AUTOSAR XML (schema 00044)
package /ECUSystem
  ecu instance ECM: associated-com-i-pdu-group=PduGroup_2aab989138b64636877a7f761b5a08a8_Rx
    can communication controller ECM
    can communication connector CAN_ECM_Connector: comm-controller=ECM
package /Communication/ISignal
  86 x i signal, all with data-type-policy=OVERRIDE:
    ECU_Data_Dwp: init-value=Signal_ECU_Data_Dwp:0.0, length=1, base-type=APPLICATION1, compu-method=DataTypeSemantics/ECU_Data_Dwp_COMPU, system-signal=Signal/ECU_Data_Dwp
    ECU_Data_NXCellDiagRqst: init-value=Signal_ECU_Data_NXCellDiagRqst:0.0, length=2, base-type=APPLICATION2, compu-method=DataTypeSemantics/ECU_Data_NXCellDiagRqst_COMPU, system-signal=Signal/ECU_Data_NXCellDiagRqst
    ECU_Data_Random_Number_Byte{0..7}: init-value=Signal_ECU_Data_Random_Number_Byte{0..7}:0, length=8, base-type=APPLICATION8, compu {phys=raw for raw 0..255}, system-signal=Signal/ECU_Data_Random_Number_Byte{0..7}
    ECU_Data_SymKey1_Byte{0..7}: init-value=Signal_ECU_Data_SymKey1_Byte{0..7}:0, length=8, base-type=APPLICATION8, compu {phys=raw for raw 0..255}, system-signal=Signal/ECU_Data_SymKey1_Byte{0..7}
    ECU_Data_SymKey2_Byte{10..15}: init-value=Signal_ECU_Data_SymKey2_Byte{10..15}:0, length=8, base-type=APPLICATION8, compu {phys=raw for raw 0..255}, system-signal=Signal/ECU_Data_SymKey2_Byte{10..15}
    ECU_Data_SymKey2_Byte8: init-value=Signal_ECU_Data_SymKey2_Byte8:0, length=8, base-type=APPLICATION8, compu {phys=raw for raw 0..255}, system-signal=Signal/ECU_Data_SymKey2_Byte8
    ECU_Data_SymKey2_Byte9: init-value=Signal_ECU_Data_SymKey2_Byte9:0, length=8, base-type=APPLICATION8, compu {phys=raw for raw 0..255}, system-signal=Signal/ECU_Data_SymKey2_Byte9
    NXSI_CALID1_Byte{0..7}: init-value=Signal_NXSI_CALID1_Byte{0..7}:0.0, length=8, base-type=APPLICATION8, compu {phys=raw for raw 0..255}, system-signal=Signal/NXSI_CALID1_Byte{0..7}
    NXSI_CALID2_Byte{10..15}: init-value=Signal_NXSI_CALID2_Byte{10..15}:0.0, length=8, base-type=APPLICATION8, compu {phys=raw for raw 0..255}, system-signal=Signal/NXSI_CALID2_Byte{10..15}
    NXSI_CALID2_Byte8: init-value=Signal_NXSI_CALID2_Byte8:0.0, length=8, base-type=APPLICATION8, compu {phys=raw for raw 0..255}, system-signal=Signal/NXSI_CALID2_Byte8
    NXSI_CALID2_Byte9: init-value=Signal_NXSI_CALID2_Byte9:0.0, length=8, base-type=APPLICATION8, compu {phys=raw for raw 0..255}, system-signal=Signal/NXSI_CALID2_Byte9
    NXSI_CVNSCU_CVN: init-value=Signal_NXSI_CVNSCU_CVN:0.0, length=32, base-type=APPLICATION32, compu {phys=raw for raw 0..2147483647}, system-signal=Signal/NXSI_CVNSCU_CVN
    NXSI_CVNSCU_CVNSt: init-value=Signal_NXSI_CVNSCU_CVNSt:0.0, length=1, base-type=APPLICATION1, compu-method=DataTypeSemantics/NXSI_CVNSCU_CVNSt_COMPU, system-signal=Signal/NXSI_CVNSCU_CVNSt
    NXSI_CVNSCU_HWver: init-value=Signal_NXSI_CVNSCU_HWver:0.0, length=12, base-type=APPLICATION12, compu {phys=raw for raw 0..4095}, system-signal=Signal/NXSI_CVNSCU_HWver
    NXSI_CVNSCU_SWver: init-value=Signal_NXSI_CVNSCU_SWver:0.0, length=12, base-type=APPLICATION12, compu {phys=raw for raw 0..4095}, system-signal=Signal/NXSI_CVNSCU_SWver
    NXSI_Data_DwpRx: init-value=Signal_NXSI_Data_DwpRx:0.0, length=1, base-type=APPLICATION1, compu-method=DataTypeSemantics/NXSI_Data_DwpRx_COMPU, system-signal=Signal/NXSI_Data_DwpRx
    NXSI_Data_NOx: init-value=Signal_NXSI_Data_NOx:0, length=16, base-type=APPLICATION16, compu {phys=raw*0.05-200 for raw 0..65535; unit Unit_ppm}, system-signal=Signal/NXSI_Data_NOx
    NXSI_Data_NOxSt: init-value=Signal_NXSI_Data_NOxSt:0.0, length=2, base-type=APPLICATION2, compu-method=DataTypeSemantics/NXSI_Data_NOxSt_COMPU, system-signal=Signal/NXSI_Data_NOxSt
    NXSI_Data_O2St: init-value=Signal_NXSI_Data_O2St:0.0, length=2, base-type=APPLICATION2, compu-method=DataTypeSemantics/NXSI_Data_O2St_COMPU, system-signal=Signal/NXSI_Data_O2St
    NXSI_Data_O2binary: init-value=Signal_NXSI_Data_O2binary:-0.081596375, length=12, base-type=APPLICATION12, compu {phys=raw*0.3152-100 for raw 0..4095; unit Unit_mV}, system-signal=Signal/NXSI_Data_O2binary
    NXSI_Data_O2linear: init-value=Signal_NXSI_Data_O2linear:-9.39, length=16, base-type=APPLICATION16, compu {phys=raw*0.00061-10 for raw 0..65535; unit Unit_%}, system-signal=Signal/NXSI_Data_O2linear
    NXSI_Data_ProbeTempSt: init-value=Signal_NXSI_Data_ProbeTempSt:0.0, length=2, base-type=APPLICATION2, compu-method=DataTypeSemantics/NXSI_Data_ProbeTempSt_COMPU, system-signal=Signal/NXSI_Data_ProbeTempSt
    NXSI_Data_SCUTempSt: init-value=Signal_NXSI_Data_SCUTempSt:0, length=2, base-type=APPLICATION2, compu-method=DataTypeSemantics/NXSI_Data_SCUTempSt_COMPU, system-signal=Signal/NXSI_Data_SCUTempSt
    NXSI_Data_SecOc_TxToggle: init-value=Signal_NXSI_Data_SecOc_TxToggle:0, length=1, base-type=APPLICATION1, compu-method=DataTypeSemantics/NXSI_Data_SecOc_TxToggle_COMPU, system-signal=Signal/NXSI_Data_SecOc_TxToggle
    NXSI_Data_diagHtr: init-value=Signal_NXSI_Data_diagHtr:0, length=3, base-type=APPLICATION3, compu-method=DataTypeSemantics/NXSI_Data_diagHtr_COMPU, system-signal=Signal/NXSI_Data_diagHtr
    NXSI_Data_diagProbe: init-value=Signal_NXSI_Data_diagProbe:0.0, length=3, base-type=APPLICATION3, compu-method=DataTypeSemantics/NXSI_Data_diagProbe_COMPU, system-signal=Signal/NXSI_Data_diagProbe
    NXSI_Data_diagVltg: init-value=Signal_NXSI_Data_diagVltg:0, length=2, base-type=APPLICATION2, compu-method=DataTypeSemantics/NXSI_Data_diagVltg_COMPU, system-signal=Signal/NXSI_Data_diagVltg
    NXSI_DiagCorrLC_LftCnt: init-value=Signal_NXSI_DiagCorrLC_LftCnt:0.0, length=24, base-type=APPLICATION24, compu {phys=raw for raw 0..16777215; unit Unit_min}, system-signal=Signal/NXSI_DiagCorrLC_LftCnt
    NXSI_DiagCorrLC_NOxPCorr: init-value=Signal_NXSI_DiagCorrLC_NOxPCorr:0.0, length=8, base-type=APPLICATION8, compu {phys=raw*0.005 for raw 0..255}, system-signal=Signal/NXSI_DiagCorrLC_NOxPCorr
    NXSI_DiagCorrLC_O2PCorr: init-value=Signal_NXSI_DiagCorrLC_O2PCorr:0.0, length=8, base-type=APPLICATION8, compu {phys=raw*0.005 for raw 0..255}, system-signal=Signal/NXSI_DiagCorrLC_O2PCorr
    NXSI_DiagCorrLC_diagCOM: init-value=Signal_NXSI_DiagCorrLC_diagCOM:0.0, length=3, base-type=APPLICATION3, compu-method=DataTypeSemantics/NXSI_DiagCorrLC_diagCOM_COMPU, system-signal=Signal/NXSI_DiagCorrLC_diagCOM
    NXSI_DiagCorrLC_diagP1: init-value=Signal_NXSI_DiagCorrLC_diagP1:0.0, length=3, base-type=APPLICATION3, compu-method=DataTypeSemantics/NXSI_DiagCorrLC_diagP1_COMPU, system-signal=Signal/NXSI_DiagCorrLC_diagP1
    NXSI_DiagCorrLC_diagP2: init-value=Signal_NXSI_DiagCorrLC_diagP2:0.0, length=3, base-type=APPLICATION3, compu-method=DataTypeSemantics/NXSI_DiagCorrLC_diagP2_COMPU, system-signal=Signal/NXSI_DiagCorrLC_diagP2
    NXSI_DiagCorrLC_diagVs: init-value=Signal_NXSI_DiagCorrLC_diagVs:0.0, length=3, base-type=APPLICATION3, compu-method=DataTypeSemantics/NXSI_DiagCorrLC_diagVs_COMPU, system-signal=Signal/NXSI_DiagCorrLC_diagVs
    NXSI_KeyResponse_Byte0: init-value=Signal_NXSI_KeyResponse_Byte0:0, length=8, base-type=APPLICATION8, compu-method=DataTypeSemantics/NXSI_KeyResponse_Byte0_COMPU, system-signal=Signal/NXSI_KeyResponse_Byte0
    NXSI_KeyResponse_Byte{1..7}: init-value=Signal_NXSI_KeyResponse_Byte{1..7}:0, length=8, base-type=APPLICATION8, compu {phys=raw for raw 0..255}, system-signal=Signal/NXSI_KeyResponse_Byte{1..7}
    NXSI_MAC_Byte{0..7}: init-value=Signal_NXSI_MAC_Byte{0..7}:0, length=8, base-type=APPLICATION8, compu {phys=raw for raw 0..255}, system-signal=Signal/NXSI_MAC_Byte{0..7}
    NXSI_NH3SD_NXCellDiagSt: init-value=Signal_NXSI_NH3SD_NXCellDiagSt:0.0, length=8, base-type=APPLICATION8, compu-method=DataTypeSemantics/NXSI_NH3SD_NXCellDiagSt_COMPU, system-signal=Signal/NXSI_NH3SD_NXCellDiagSt
    NXSI_NH3SD_NxCellDiagRes: init-value=Signal_NXSI_NH3SD_NxCellDiagRes:0.0, length=8, base-type=APPLICATION8, compu {phys=raw for raw 0..255; unit Unit_%}, system-signal=Signal/NXSI_NH3SD_NxCellDiagRes
    NXSI_NH3SD_RpVs: init-value=Signal_NXSI_NH3SD_RpVs:0.0, length=16, base-type=APPLICATION16, compu {phys=raw*0.01 for raw 0..65535; unit Unit_Ohm}, system-signal=Signal/NXSI_NH3SD_RpVs
    NXSI_NH3SD_SupplyVltg: init-value=Signal_NXSI_NH3SD_SupplyVltg:0.0, length=16, base-type=APPLICATION16, compu {phys=raw*0.5 for raw 0..65535; unit Unit_mV}, system-signal=Signal/NXSI_NH3SD_SupplyVltg
    NXSI_NH3SD_corNH3: init-value=Signal_NXSI_NH3SD_corNH3:0.0, length=16, base-type=APPLICATION16, compu {phys=raw*0.005 for raw 0..65535}, system-signal=Signal/NXSI_NH3SD_corNH3
package /Signal
  86 x system signal:
    ECU_Data_Dwp: compu-method=DataTypeSemantics/ECU_Data_Dwp_COMPU
    ECU_Data_NXCellDiagRqst: compu-method=DataTypeSemantics/ECU_Data_NXCellDiagRqst_COMPU
    ECU_Data_Random_Number_Byte{0..7}: compu {phys=raw for raw 0..255}
    ECU_Data_SymKey1_Byte{0..7}: compu {phys=raw for raw 0..255}
    ECU_Data_SymKey2_Byte{10..15}: compu {phys=raw for raw 0..255}
    ECU_Data_SymKey2_Byte8: compu {phys=raw for raw 0..255}
    ECU_Data_SymKey2_Byte9: compu {phys=raw for raw 0..255}
    NXSI_CALID1_Byte{0..7}: compu {phys=raw for raw 0..255}
    NXSI_CALID2_Byte{10..15}: compu {phys=raw for raw 0..255}
    NXSI_CALID2_Byte8: compu {phys=raw for raw 0..255}
    NXSI_CALID2_Byte9: compu {phys=raw for raw 0..255}
    NXSI_CVNSCU_CVN: compu {phys=raw for raw 0..2147483647}
    NXSI_CVNSCU_CVNSt: compu-method=DataTypeSemantics/NXSI_CVNSCU_CVNSt_COMPU
    NXSI_CVNSCU_HWver: compu {phys=raw for raw 0..4095}
    NXSI_CVNSCU_SWver: compu {phys=raw for raw 0..4095}
    NXSI_Data_DwpRx: compu-method=DataTypeSemantics/NXSI_Data_DwpRx_COMPU
    NXSI_Data_NOx: compu {phys=raw*0.05-200 for raw 0..65535; unit Unit_ppm}
    NXSI_Data_NOxSt: compu-method=DataTypeSemantics/NXSI_Data_NOxSt_COMPU
    NXSI_Data_O2St: compu-method=DataTypeSemantics/NXSI_Data_O2St_COMPU
    NXSI_Data_O2binary: compu {phys=raw*0.3152-100 for raw 0..4095; unit Unit_mV}
    NXSI_Data_O2linear: compu {phys=raw*0.00061-10 for raw 0..65535; unit Unit_%}
    NXSI_Data_ProbeTempSt: compu-method=DataTypeSemantics/NXSI_Data_ProbeTempSt_COMPU
    NXSI_Data_SCUTempSt: compu-method=DataTypeSemantics/NXSI_Data_SCUTempSt_COMPU
    NXSI_Data_SecOc_TxToggle: compu-method=DataTypeSemantics/NXSI_Data_SecOc_TxToggle_COMPU
    NXSI_Data_diagHtr: compu-method=DataTypeSemantics/NXSI_Data_diagHtr_COMPU
    NXSI_Data_diagProbe: compu-method=DataTypeSemantics/NXSI_Data_diagProbe_COMPU
    NXSI_Data_diagVltg: compu-method=DataTypeSemantics/NXSI_Data_diagVltg_COMPU
    NXSI_DiagCorrLC_LftCnt: compu {phys=raw for raw 0..16777215; unit Unit_min}
    NXSI_DiagCorrLC_NOxPCorr: compu {phys=raw*0.005 for raw 0..255}
    NXSI_DiagCorrLC_O2PCorr: compu {phys=raw*0.005 for raw 0..255}
    NXSI_DiagCorrLC_diagCOM: compu-method=DataTypeSemantics/NXSI_DiagCorrLC_diagCOM_COMPU
    NXSI_DiagCorrLC_diagP1: compu-method=DataTypeSemantics/NXSI_DiagCorrLC_diagP1_COMPU
    NXSI_DiagCorrLC_diagP2: compu-method=DataTypeSemantics/NXSI_DiagCorrLC_diagP2_COMPU
    NXSI_DiagCorrLC_diagVs: compu-method=DataTypeSemantics/NXSI_DiagCorrLC_diagVs_COMPU
    NXSI_KeyResponse_Byte0: compu-method=DataTypeSemantics/NXSI_KeyResponse_Byte0_COMPU
    NXSI_KeyResponse_Byte{1..7}: compu {phys=raw for raw 0..255}
    NXSI_MAC_Byte{0..7}: compu {phys=raw for raw 0..255}
    NXSI_NH3SD_NXCellDiagSt: compu-method=DataTypeSemantics/NXSI_NH3SD_NXCellDiagSt_COMPU
    NXSI_NH3SD_NxCellDiagRes: compu {phys=raw for raw 0..255; unit Unit_%}
    NXSI_NH3SD_RpVs: compu {phys=raw*0.01 for raw 0..65535; unit Unit_Ohm}
    NXSI_NH3SD_SupplyVltg: compu {phys=raw*0.5 for raw 0..65535; unit Unit_mV}
    NXSI_NH3SD_corNH3: compu {phys=raw*0.005 for raw 0..65535}
package /DataType/DataTypeSemantics
  compu method ECU_Data_Dwp_COMPU: phys=raw for raw 0..1, 1=Dew_point_end_reached (New_Short_Label), 0=Dew_point_end_not_reached (New_Short_Label); unit Unit_SED
  compu method ECU_Data_Dwp_COMPU: phys=raw for raw 0..1, 1=Dew_point_end_reached (New_Short_Label), 0=Dew_point_end_not_reached (New_Short_Label); unit Unit_SED
  compu method ECU_Data_NXCellDiagRqst_COMPU: phys=raw for raw 0..3, 3=not_applicable (New_Short_Label), 2=active_in_idle/thrust (New_Short_Label), 1=active_in_after_run (New_Short_Label), 0=not_active (New_Short_Label); unit Unit_SED
  compu method ECU_Data_NXCellDiagRqst_COMPU: phys=raw for raw 0..3, 3=not_applicable (New_Short_Label), 2=active_in_idle/thrust (New_Short_Label), 1=active_in_after_run (New_Short_Label), 0=not_active (New_Short_Label); unit Unit_SED
  compu method ECU_Data_Random_Number_Byte{0..7}_COMPU: phys=raw for raw 0..255
  compu method ECU_Data_SymKey1_Byte{0..7}_COMPU: phys=raw for raw 0..255
  compu method ECU_Data_SymKey2_Byte{10..15}_COMPU: phys=raw for raw 0..255
  compu method ECU_Data_SymKey2_Byte8_COMPU: phys=raw for raw 0..255
  compu method ECU_Data_SymKey2_Byte9_COMPU: phys=raw for raw 0..255
  compu method NXSI_CALID1_Byte{0..7}_COMPU: phys=raw for raw 0..255
  compu method NXSI_CALID2_Byte{10..15}_COMPU: phys=raw for raw 0..255
  compu method NXSI_CALID2_Byte8_COMPU: phys=raw for raw 0..255
  compu method NXSI_CALID2_Byte9_COMPU: phys=raw for raw 0..255
  compu method NXSI_CVNSCU_CVNSt_COMPU: phys=raw for raw 0..1, 1=calculation_done (New_Short_Label), 0=calculation_in_progress (New_Short_Label)
  compu method NXSI_CVNSCU_CVNSt_COMPU: phys=raw for raw 0..1, 1=calculation_done (New_Short_Label), 0=calculation_in_progress (New_Short_Label)
  compu method NXSI_CVNSCU_CVN_COMPU: phys=raw for raw 0..2147483647
  compu method NXSI_CVNSCU_HWver_COMPU: phys=raw for raw 0..4095
  compu method NXSI_CVNSCU_SWver_COMPU: phys=raw for raw 0..4095
  compu method NXSI_Data_DwpRx_COMPU: phys=raw for raw 0..1, 1=reached (New_Short_Label), 0=not_reached (New_Short_Label); unit Unit_SED
  compu method NXSI_Data_DwpRx_COMPU: phys=raw for raw 0..1, 1=reached (New_Short_Label), 0=not_reached (New_Short_Label); unit Unit_SED
  compu method NXSI_Data_NOxSt_COMPU: phys=raw for raw 0..3, 3=reserved (New_Short_Label), 2=YELLOW(out_of_specification) (New_Short_Label), 1=GREEN(valid,_in_specification) (New_Short_Label), 0=RED(invalid) (New_Short_Label); unit Unit_0
  compu method NXSI_Data_NOxSt_COMPU: phys=raw for raw 0..3, 3=reserved (New_Short_Label), 2=YELLOW(out_of_specification) (New_Short_Label), 1=GREEN(valid,_in_specification) (New_Short_Label), 0=RED(invalid) (New_Short_Label); unit Unit_0
  compu method NXSI_Data_NOx_COMPU: phys=raw*0.05-200 for raw 0..65535; unit Unit_ppm
  compu method NXSI_Data_O2St_COMPU: phys=raw for raw 0..3, 3=reserved (New_Short_Label), 2=YELLOW(out_of_specification) (New_Short_Label), 1=GREEN(valid,_in_specification) (New_Short_Label), 0=RED(invalid) (New_Short_Label); unit Unit_0
  compu method NXSI_Data_O2St_COMPU: phys=raw for raw 0..3, 3=reserved (New_Short_Label), 2=YELLOW(out_of_specification) (New_Short_Label), 1=GREEN(valid,_in_specification) (New_Short_Label), 0=RED(invalid) (New_Short_Label); unit Unit_0
  compu method NXSI_Data_O2binary_COMPU: phys=raw*0.3152-100 for raw 0..4095; unit Unit_mV
  compu method NXSI_Data_O2linear_COMPU: phys=raw*0.00061-10 for raw 0..65535; unit Unit_%
  compu method NXSI_Data_ProbeTempSt_COMPU: phys=raw for raw 0..3, 3=reserved (New_Short_Label), 2=reserved (New_Short_Label), 1=reached_CL_operation_point (New_Short_Label), 0=not_reached_CL_operation_point (New_Short_Label)
  compu method NXSI_Data_ProbeTempSt_COMPU: phys=raw for raw 0..3, 3=reserved (New_Short_Label), 2=reserved (New_Short_Label), 1=reached_CL_operation_point (New_Short_Label), 0=not_reached_CL_operation_point (New_Short_Label)
  compu method NXSI_Data_SCUTempSt_COMPU: phys=raw for raw 0..3, 3=reserved (New_Short_Label), 2=SCU_over_temperature (New_Short_Label), 1=SCU_temperature_in_range (New_Short_Label), 0=SCU_temperature_not_available (New_Short_Label)
  compu method NXSI_Data_SCUTempSt_COMPU: phys=raw for raw 0..3, 3=reserved (New_Short_Label), 2=SCU_over_temperature (New_Short_Label), 1=SCU_temperature_in_range (New_Short_Label), 0=SCU_temperature_not_available (New_Short_Label)
  compu method NXSI_Data_SecOc_TxToggle_COMPU: phys=raw for raw 0..1, 1=Toggle_set (New_Short_Label), 0=Toggle_reset (New_Short_Label)
  compu method NXSI_Data_SecOc_TxToggle_COMPU: phys=raw for raw 0..1, 1=Toggle_set (New_Short_Label), 0=Toggle_reset (New_Short_Label)
  compu method NXSI_Data_diagHtr_COMPU: phys=raw for raw 0..7, 7=reserved (New_Short_Label), 6=reserved (New_Short_Label), 5=reserved (New_Short_Label), 4=open_circuit (New_Short_Label), 3=short_to_battery (New_Short_Label), 2=short_to_GND (New_Short_Label), 1=no_error (New_Short_Label), 0=diag_not_executed (New_Short_Label); unit Unit_0
  compu method NXSI_Data_diagHtr_COMPU: phys=raw for raw 0..7, 7=reserved (New_Short_Label), 6=reserved (New_Short_Label), 5=reserved (New_Short_Label), 4=open_circuit (New_Short_Label), 3=short_to_battery (New_Short_Label), 2=short_to_GND (New_Short_Label), 1=no_error (New_Short_Label), 0=diag_not_executed (New_Short_Label); unit Unit_0
  compu method NXSI_Data_diagProbe_COMPU: phys=raw for raw 0..7, 7=reserved (New_Short_Label), 6=reserved (New_Short_Label), 5=reserved (New_Short_Label), 4=open_circuit (New_Short_Label), 3=short_to_battery (New_Short_Label), 2=short_to_GND (New_Short_Label), 1=no_error (New_Short_Label), 0=diag_not_executed (New_Short_Label); unit Unit_0
  compu method NXSI_Data_diagProbe_COMPU: phys=raw for raw 0..7, 7=reserved (New_Short_Label), 6=reserved (New_Short_Label), 5=reserved (New_Short_Label), 4=open_circuit (New_Short_Label), 3=short_to_battery (New_Short_Label), 2=short_to_GND (New_Short_Label), 1=no_error (New_Short_Label), 0=diag_not_executed (New_Short_Label); unit Unit_0
  compu method NXSI_Data_diagVltg_COMPU: phys=raw for raw 0..3, 3=Battery_undervoltage (New_Short_Label), 2=Battery_OV(includes_fast_OV) (New_Short_Label), 1=no_error (New_Short_Label), 0=diagnosis_not_executed (New_Short_Label)
  compu method NXSI_Data_diagVltg_COMPU: phys=raw for raw 0..3, 3=Battery_undervoltage (New_Short_Label), 2=Battery_OV(includes_fast_OV) (New_Short_Label), 1=no_error (New_Short_Label), 0=diagnosis_not_executed (New_Short_Label)
  compu method NXSI_DiagCorrLC_LftCnt_COMPU: phys=raw for raw 0..16777215; unit Unit_min
  compu method NXSI_DiagCorrLC_NOxPCorr_COMPU: phys=raw*0.005 for raw 0..255
  compu method NXSI_DiagCorrLC_O2PCorr_COMPU: phys=raw*0.005 for raw 0..255
  compu method NXSI_DiagCorrLC_diagCOM_COMPU: phys=raw for raw 0..7, 7=reserved (New_Short_Label), 6=reserved (New_Short_Label), 5=reserved (New_Short_Label), 4=open_circuit (New_Short_Label), 3=short_to_battery (New_Short_Label), 2=short_to_GND (New_Short_Label), 1=no_error (New_Short_Label), 0=diag_not_executed (New_Short_Label); unit Unit_0
  compu method NXSI_DiagCorrLC_diagCOM_COMPU: phys=raw for raw 0..7, 7=reserved (New_Short_Label), 6=reserved (New_Short_Label), 5=reserved (New_Short_Label), 4=open_circuit (New_Short_Label), 3=short_to_battery (New_Short_Label), 2=short_to_GND (New_Short_Label), 1=no_error (New_Short_Label), 0=diag_not_executed (New_Short_Label); unit Unit_0
  compu method NXSI_DiagCorrLC_diagP1_COMPU: phys=raw for raw 0..7, 7=reserved (New_Short_Label), 6=reserved (New_Short_Label), 5=reserved (New_Short_Label), 4=open_circuit (New_Short_Label), 3=short_to_battery (New_Short_Label), 2=short_to_GND (New_Short_Label), 1=no_error (New_Short_Label), 0=diag_not_executed (New_Short_Label); unit Unit_0
  compu method NXSI_DiagCorrLC_diagP1_COMPU: phys=raw for raw 0..7, 7=reserved (New_Short_Label), 6=reserved (New_Short_Label), 5=reserved (New_Short_Label), 4=open_circuit (New_Short_Label), 3=short_to_battery (New_Short_Label), 2=short_to_GND (New_Short_Label), 1=no_error (New_Short_Label), 0=diag_not_executed (New_Short_Label); unit Unit_0
  compu method NXSI_DiagCorrLC_diagP2_COMPU: phys=raw for raw 0..7, 7=reserved (New_Short_Label), 6=reserved (New_Short_Label), 5=reserved (New_Short_Label), 4=open_circuit (New_Short_Label), 3=short_to_battery (New_Short_Label), 2=short_to_GND (New_Short_Label), 1=no_error (New_Short_Label), 0=diag_not_executed (New_Short_Label); unit Unit_0
  compu method NXSI_DiagCorrLC_diagP2_COMPU: phys=raw for raw 0..7, 7=reserved (New_Short_Label), 6=reserved (New_Short_Label), 5=reserved (New_Short_Label), 4=open_circuit (New_Short_Label), 3=short_to_battery (New_Short_Label), 2=short_to_GND (New_Short_Label), 1=no_error (New_Short_Label), 0=diag_not_executed (New_Short_Label); unit Unit_0
  compu method NXSI_DiagCorrLC_diagVs_COMPU: phys=raw for raw 0..7, 7=reserved (New_Short_Label), 6=reserved (New_Short_Label), 5=reserved (New_Short_Label), 4=open_circuit (New_Short_Label), 3=short_to_battery (New_Short_Label), 2=short_to_GND (New_Short_Label), 1=no_error (New_Short_Label), 0=diag_not_executed (New_Short_Label); unit Unit_0
  compu method NXSI_DiagCorrLC_diagVs_COMPU: phys=raw for raw 0..7, 7=reserved (New_Short_Label), 6=reserved (New_Short_Label), 5=reserved (New_Short_Label), 4=open_circuit (New_Short_Label), 3=short_to_battery (New_Short_Label), 2=short_to_GND (New_Short_Label), 1=no_error (New_Short_Label), 0=diag_not_executed (New_Short_Label); unit Unit_0
  compu method NXSI_KeyResponse_Byte0_COMPU: phys=raw for raw 0..255, 1=Negative_response (New_Short_Label), 0=Positive_response (New_Short_Label)
  compu method NXSI_KeyResponse_Byte0_COMPU: phys=raw for raw 0..255, 1=Negative_response (New_Short_Label), 0=Positive_response (New_Short_Label)
  compu method NXSI_KeyResponse_Byte{1..7}_COMPU: phys=raw for raw 0..255
  compu method NXSI_MAC_Byte{0..7}_COMPU: phys=raw for raw 0..255
  compu method NXSI_NH3SD_NXCellDiagSt_COMPU: phys=raw for raw 0..255, 3=reserved (New_Short_Label), 4=completed (New_Short_Label), 2=aborted (New_Short_Label), 1=active (New_Short_Label), 0=inactive (New_Short_Label)
  compu method NXSI_NH3SD_NXCellDiagSt_COMPU: phys=raw for raw 0..255, 3=reserved (New_Short_Label), 4=completed (New_Short_Label), 2=aborted (New_Short_Label), 1=active (New_Short_Label), 0=inactive (New_Short_Label)
  compu method NXSI_NH3SD_NxCellDiagRes_COMPU: phys=raw for raw 0..255; unit Unit_%
  compu method NXSI_NH3SD_RpVs_COMPU: phys=raw*0.01 for raw 0..65535; unit Unit_Ohm
  compu method NXSI_NH3SD_SupplyVltg_COMPU: phys=raw*0.5 for raw 0..65535; unit Unit_mV
  compu method NXSI_NH3SD_corNH3_COMPU: phys=raw*0.005 for raw 0..65535
package /DataType/DataTypeSemantics/SwBaseTypes
  8 x base type, all with category=FIXED_LENGTH, base-type-encoding=NONE:
    APPLICATION1: base-type-size=1
    APPLICATION12: base-type-size=12
    APPLICATION16: base-type-size=16
    APPLICATION2: base-type-size=2
    APPLICATION24: base-type-size=24
    APPLICATION3: base-type-size=3
    APPLICATION32: base-type-size=32
    APPLICATION8: base-type-size=8
package /DataType/Unit
  7 x unit, all with factor-si-to-unit=1:
    %: display-name=Unit_%
    0: display-name=Unit_0
    Ohm: display-name=Unit_Ohm
    SED: display-name=Unit_SED
    mV: display-name=Unit_mV
    min: display-name=Unit_min
    ppm: display-name=Unit_ppm
package /VehicleTopology
  can cluster CAN_ECM_Cluster: protocol-name=CAN-FD
    can physical channel PhCn_CAN_ECM: comm-connectors=CAN_ECM_Connector
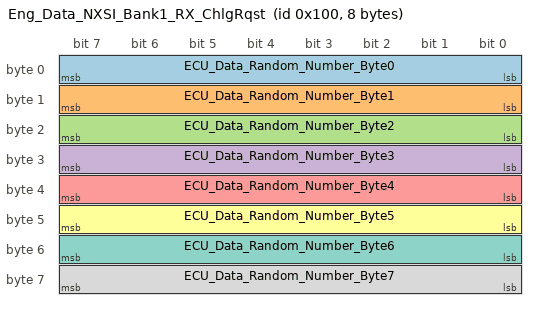
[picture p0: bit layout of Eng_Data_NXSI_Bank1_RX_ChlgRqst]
      frame Eng_Data_NXSI_Bank1_RX_ChlgRqst: id 0x100, from ECM, frame-length=8, can-addressing-mode=STANDARD, can-fd-frame-support=false, can-frame-rx-behavior=CAN-20, can-frame-tx-behavior=CAN-20
        carries pdu Eng_Data_NXSI_Bank1_RX_ChlgRqst: packing-byte-order=big-endian, start-position=7
        pdu Eng_Data_NXSI_Bank1_RX_ChlgRqst: length=8, unused-bit-pattern=0
          signal ECU_Data_Random_Number_Byte0: start 7, 8 bit, big-endian, data-type-policy=OVERRIDE, init-value=Signal_ECU_Data_Random_Number_Byte0:0, base-type=APPLICATION8, compu {phys=raw for raw 0..255}, transfer-property=PENDING
          signal ECU_Data_Random_Number_Byte1: start 15, 8 bit, big-endian, data-type-policy=OVERRIDE, init-value=Signal_ECU_Data_Random_Number_Byte1:0, base-type=APPLICATION8, compu {phys=raw for raw 0..255}, transfer-property=PENDING
          signal ECU_Data_Random_Number_Byte2: start 23, 8 bit, big-endian, data-type-policy=OVERRIDE, init-value=Signal_ECU_Data_Random_Number_Byte2:0, base-type=APPLICATION8, compu {phys=raw for raw 0..255}, transfer-property=PENDING
          signal ECU_Data_Random_Number_Byte3: start 31, 8 bit, big-endian, data-type-policy=OVERRIDE, init-value=Signal_ECU_Data_Random_Number_Byte3:0, base-type=APPLICATION8, compu {phys=raw for raw 0..255}, transfer-property=PENDING
          signal ECU_Data_Random_Number_Byte4: start 39, 8 bit, big-endian, data-type-policy=OVERRIDE, init-value=Signal_ECU_Data_Random_Number_Byte4:0, base-type=APPLICATION8, compu {phys=raw for raw 0..255}, transfer-property=PENDING
          signal ECU_Data_Random_Number_Byte5: start 47, 8 bit, big-endian, data-type-policy=OVERRIDE, init-value=Signal_ECU_Data_Random_Number_Byte5:0, base-type=APPLICATION8, compu {phys=raw for raw 0..255}, transfer-property=PENDING
          signal ECU_Data_Random_Number_Byte6: start 55, 8 bit, big-endian, data-type-policy=OVERRIDE, init-value=Signal_ECU_Data_Random_Number_Byte6:0, base-type=APPLICATION8, compu {phys=raw for raw 0..255}, transfer-property=PENDING
          signal ECU_Data_Random_Number_Byte7: start 63, 8 bit, big-endian, data-type-policy=OVERRIDE, init-value=Signal_ECU_Data_Random_Number_Byte7:0, base-type=APPLICATION8, compu {phys=raw for raw 0..255}, transfer-property=PENDING
      frame Eng_Data_NXSI_Bank1_RX_Data: id 0x3A5, from ECM, frame-length=8, can-addressing-mode=STANDARD, can-fd-frame-support=false, can-frame-rx-behavior=CAN-20, can-frame-tx-behavior=CAN-20
        carries pdu Eng_Data_NXSI_Bank1_RX_Data: packing-byte-order=big-endian, start-position=7
        pdu Eng_Data_NXSI_Bank1_RX_Data: length=8, transmission-mode-true-timing=cyclic-timing=time-period=0.1, unused-bit-pattern=0
          signal ECU_Data_Dwp: start 0, 1 bit, big-endian, data-type-policy=OVERRIDE, init-value=Signal_ECU_Data_Dwp:0, base-type=APPLICATION1, compu-method=DataTypeSemantics/ECU_Data_Dwp_COMPU, transfer-property=PENDING
          signal ECU_Data_NXCellDiagRqst: start 2, 2 bit, big-endian, data-type-policy=OVERRIDE, init-value=Signal_ECU_Data_NXCellDiagRqst:0, base-type=APPLICATION2, compu-method=DataTypeSemantics/ECU_Data_NXCellDiagRqst_COMPU, transfer-property=PENDING
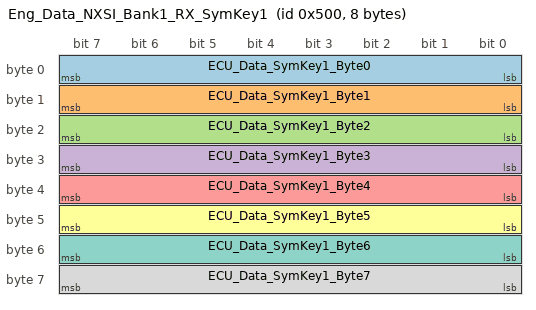
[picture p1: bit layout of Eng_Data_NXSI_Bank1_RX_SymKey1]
      frame Eng_Data_NXSI_Bank1_RX_SymKey1: id 0x500, from ECM, frame-length=8, can-addressing-mode=STANDARD, can-fd-frame-support=false, can-frame-rx-behavior=CAN-20, can-frame-tx-behavior=CAN-20
        carries pdu Eng_Data_NXSI_Bank1_RX_SymKey1: packing-byte-order=big-endian, start-position=7
        pdu Eng_Data_NXSI_Bank1_RX_SymKey1: length=8, unused-bit-pattern=0
          signal ECU_Data_SymKey1_Byte0: start 7, 8 bit, big-endian, data-type-policy=OVERRIDE, init-value=Signal_ECU_Data_SymKey1_Byte0:0, base-type=APPLICATION8, compu {phys=raw for raw 0..255}, transfer-property=PENDING
          signal ECU_Data_SymKey1_Byte1: start 15, 8 bit, big-endian, data-type-policy=OVERRIDE, init-value=Signal_ECU_Data_SymKey1_Byte1:0, base-type=APPLICATION8, compu {phys=raw for raw 0..255}, transfer-property=PENDING
          signal ECU_Data_SymKey1_Byte2: start 23, 8 bit, big-endian, data-type-policy=OVERRIDE, init-value=Signal_ECU_Data_SymKey1_Byte2:0, base-type=APPLICATION8, compu {phys=raw for raw 0..255}, transfer-property=PENDING
          signal ECU_Data_SymKey1_Byte3: start 31, 8 bit, big-endian, data-type-policy=OVERRIDE, init-value=Signal_ECU_Data_SymKey1_Byte3:0, base-type=APPLICATION8, compu {phys=raw for raw 0..255}, transfer-property=PENDING
          signal ECU_Data_SymKey1_Byte4: start 39, 8 bit, big-endian, data-type-policy=OVERRIDE, init-value=Signal_ECU_Data_SymKey1_Byte4:0, base-type=APPLICATION8, compu {phys=raw for raw 0..255}, transfer-property=PENDING
          signal ECU_Data_SymKey1_Byte5: start 47, 8 bit, big-endian, data-type-policy=OVERRIDE, init-value=Signal_ECU_Data_SymKey1_Byte5:0, base-type=APPLICATION8, compu {phys=raw for raw 0..255}, transfer-property=PENDING
          signal ECU_Data_SymKey1_Byte6: start 55, 8 bit, big-endian, data-type-policy=OVERRIDE, init-value=Signal_ECU_Data_SymKey1_Byte6:0, base-type=APPLICATION8, compu {phys=raw for raw 0..255}, transfer-property=PENDING
          signal ECU_Data_SymKey1_Byte7: start 63, 8 bit, big-endian, data-type-policy=OVERRIDE, init-value=Signal_ECU_Data_SymKey1_Byte7:0, base-type=APPLICATION8, compu {phys=raw for raw 0..255}, transfer-property=PENDING
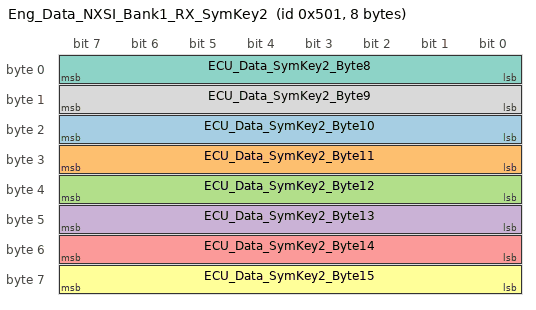
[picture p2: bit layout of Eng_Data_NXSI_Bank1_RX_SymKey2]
      frame Eng_Data_NXSI_Bank1_RX_SymKey2: id 0x501, from ECM, frame-length=8, can-addressing-mode=STANDARD, can-fd-frame-support=false, can-frame-rx-behavior=CAN-20, can-frame-tx-behavior=CAN-20
        carries pdu Eng_Data_NXSI_Bank1_RX_SymKey2: packing-byte-order=big-endian, start-position=7
        pdu Eng_Data_NXSI_Bank1_RX_SymKey2: length=8, unused-bit-pattern=0
          signal ECU_Data_SymKey2_Byte10: start 23, 8 bit, big-endian, data-type-policy=OVERRIDE, init-value=Signal_ECU_Data_SymKey2_Byte10:0, base-type=APPLICATION8, compu {phys=raw for raw 0..255}, transfer-property=PENDING
          signal ECU_Data_SymKey2_Byte11: start 31, 8 bit, big-endian, data-type-policy=OVERRIDE, init-value=Signal_ECU_Data_SymKey2_Byte11:0, base-type=APPLICATION8, compu {phys=raw for raw 0..255}, transfer-property=PENDING
          signal ECU_Data_SymKey2_Byte12: start 39, 8 bit, big-endian, data-type-policy=OVERRIDE, init-value=Signal_ECU_Data_SymKey2_Byte12:0, base-type=APPLICATION8, compu {phys=raw for raw 0..255}, transfer-property=PENDING
          signal ECU_Data_SymKey2_Byte13: start 47, 8 bit, big-endian, data-type-policy=OVERRIDE, init-value=Signal_ECU_Data_SymKey2_Byte13:0, base-type=APPLICATION8, compu {phys=raw for raw 0..255}, transfer-property=PENDING
          signal ECU_Data_SymKey2_Byte14: start 55, 8 bit, big-endian, data-type-policy=OVERRIDE, init-value=Signal_ECU_Data_SymKey2_Byte14:0, base-type=APPLICATION8, compu {phys=raw for raw 0..255}, transfer-property=PENDING
          signal ECU_Data_SymKey2_Byte15: start 63, 8 bit, big-endian, data-type-policy=OVERRIDE, init-value=Signal_ECU_Data_SymKey2_Byte15:0, base-type=APPLICATION8, compu {phys=raw for raw 0..255}, transfer-property=PENDING
          signal ECU_Data_SymKey2_Byte8: start 7, 8 bit, big-endian, data-type-policy=OVERRIDE, init-value=Signal_ECU_Data_SymKey2_Byte8:0, base-type=APPLICATION8, compu {phys=raw for raw 0..255}, transfer-property=PENDING
          signal ECU_Data_SymKey2_Byte9: start 15, 8 bit, big-endian, data-type-policy=OVERRIDE, init-value=Signal_ECU_Data_SymKey2_Byte9:0, base-type=APPLICATION8, compu {phys=raw for raw 0..255}, transfer-property=PENDING
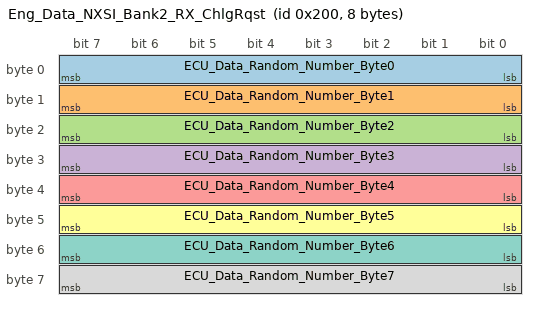
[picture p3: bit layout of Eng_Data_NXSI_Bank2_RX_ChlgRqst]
      frame Eng_Data_NXSI_Bank2_RX_ChlgRqst: id 0x200, from ECM, frame-length=8, can-addressing-mode=STANDARD, can-fd-frame-support=false, can-frame-rx-behavior=CAN-20, can-frame-tx-behavior=CAN-20
        carries pdu Eng_Data_NXSI_Bank2_RX_ChlgRqst: packing-byte-order=big-endian, start-position=7
        pdu Eng_Data_NXSI_Bank2_RX_ChlgRqst: length=8, unused-bit-pattern=0
          signal ECU_Data_Random_Number_Byte0: start 7, 8 bit, big-endian, data-type-policy=OVERRIDE, init-value=Signal_ECU_Data_Random_Number_Byte0:0, base-type=APPLICATION8, compu {phys=raw for raw 0..255}, transfer-property=PENDING
          signal ECU_Data_Random_Number_Byte1: start 15, 8 bit, big-endian, data-type-policy=OVERRIDE, init-value=Signal_ECU_Data_Random_Number_Byte1:0, base-type=APPLICATION8, compu {phys=raw for raw 0..255}, transfer-property=PENDING
          signal ECU_Data_Random_Number_Byte2: start 23, 8 bit, big-endian, data-type-policy=OVERRIDE, init-value=Signal_ECU_Data_Random_Number_Byte2:0, base-type=APPLICATION8, compu {phys=raw for raw 0..255}, transfer-property=PENDING
          signal ECU_Data_Random_Number_Byte3: start 31, 8 bit, big-endian, data-type-policy=OVERRIDE, init-value=Signal_ECU_Data_Random_Number_Byte3:0, base-type=APPLICATION8, compu {phys=raw for raw 0..255}, transfer-property=PENDING
          signal ECU_Data_Random_Number_Byte4: start 39, 8 bit, big-endian, data-type-policy=OVERRIDE, init-value=Signal_ECU_Data_Random_Number_Byte4:0, base-type=APPLICATION8, compu {phys=raw for raw 0..255}, transfer-property=PENDING
          signal ECU_Data_Random_Number_Byte5: start 47, 8 bit, big-endian, data-type-policy=OVERRIDE, init-value=Signal_ECU_Data_Random_Number_Byte5:0, base-type=APPLICATION8, compu {phys=raw for raw 0..255}, transfer-property=PENDING
          signal ECU_Data_Random_Number_Byte6: start 55, 8 bit, big-endian, data-type-policy=OVERRIDE, init-value=Signal_ECU_Data_Random_Number_Byte6:0, base-type=APPLICATION8, compu {phys=raw for raw 0..255}, transfer-property=PENDING
          signal ECU_Data_Random_Number_Byte7: start 63, 8 bit, big-endian, data-type-policy=OVERRIDE, init-value=Signal_ECU_Data_Random_Number_Byte7:0, base-type=APPLICATION8, compu {phys=raw for raw 0..255}, transfer-property=PENDING
      frame Eng_Data_NXSI_Bank2_RX_Data: id 0x2A5, from ECM, frame-length=8, can-addressing-mode=STANDARD, can-fd-frame-support=false, can-frame-rx-behavior=CAN-20, can-frame-tx-behavior=CAN-20
        carries pdu Eng_Data_NXSI_Bank2_RX_Data: packing-byte-order=big-endian, start-position=7
        pdu Eng_Data_NXSI_Bank2_RX_Data: length=8, transmission-mode-true-timing=cyclic-timing=time-period=0.1, unused-bit-pattern=0
          signal ECU_Data_Dwp: start 0, 1 bit, big-endian, data-type-policy=OVERRIDE, init-value=Signal_ECU_Data_Dwp:0, base-type=APPLICATION1, compu-method=DataTypeSemantics/ECU_Data_Dwp_COMPU, transfer-property=PENDING
          signal ECU_Data_NXCellDiagRqst: start 2, 2 bit, big-endian, data-type-policy=OVERRIDE, init-value=Signal_ECU_Data_NXCellDiagRqst:0, base-type=APPLICATION2, compu-method=DataTypeSemantics/ECU_Data_NXCellDiagRqst_COMPU, transfer-property=PENDING
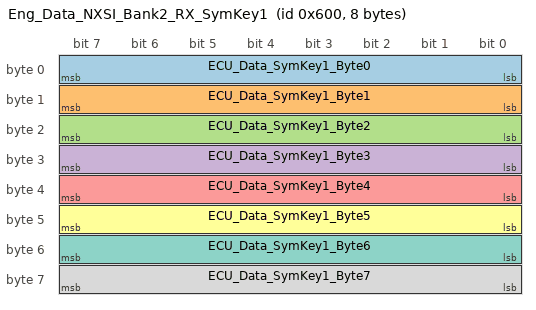
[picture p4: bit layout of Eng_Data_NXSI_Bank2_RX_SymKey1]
      frame Eng_Data_NXSI_Bank2_RX_SymKey1: id 0x600, from ECM, frame-length=8, can-addressing-mode=STANDARD, can-fd-frame-support=false, can-frame-rx-behavior=CAN-20, can-frame-tx-behavior=CAN-20
        carries pdu Eng_Data_NXSI_Bank2_RX_SymKey1: packing-byte-order=big-endian, start-position=7
        pdu Eng_Data_NXSI_Bank2_RX_SymKey1: length=8, unused-bit-pattern=0
          signal ECU_Data_SymKey1_Byte0: start 7, 8 bit, big-endian, data-type-policy=OVERRIDE, init-value=Signal_ECU_Data_SymKey1_Byte0:0, base-type=APPLICATION8, compu {phys=raw for raw 0..255}, transfer-property=PENDING
          signal ECU_Data_SymKey1_Byte1: start 15, 8 bit, big-endian, data-type-policy=OVERRIDE, init-value=Signal_ECU_Data_SymKey1_Byte1:0, base-type=APPLICATION8, compu {phys=raw for raw 0..255}, transfer-property=PENDING
          signal ECU_Data_SymKey1_Byte2: start 23, 8 bit, big-endian, data-type-policy=OVERRIDE, init-value=Signal_ECU_Data_SymKey1_Byte2:0, base-type=APPLICATION8, compu {phys=raw for raw 0..255}, transfer-property=PENDING
          signal ECU_Data_SymKey1_Byte3: start 31, 8 bit, big-endian, data-type-policy=OVERRIDE, init-value=Signal_ECU_Data_SymKey1_Byte3:0, base-type=APPLICATION8, compu {phys=raw for raw 0..255}, transfer-property=PENDING
          signal ECU_Data_SymKey1_Byte4: start 39, 8 bit, big-endian, data-type-policy=OVERRIDE, init-value=Signal_ECU_Data_SymKey1_Byte4:0, base-type=APPLICATION8, compu {phys=raw for raw 0..255}, transfer-property=PENDING
          signal ECU_Data_SymKey1_Byte5: start 47, 8 bit, big-endian, data-type-policy=OVERRIDE, init-value=Signal_ECU_Data_SymKey1_Byte5:0, base-type=APPLICATION8, compu {phys=raw for raw 0..255}, transfer-property=PENDING
          signal ECU_Data_SymKey1_Byte6: start 55, 8 bit, big-endian, data-type-policy=OVERRIDE, init-value=Signal_ECU_Data_SymKey1_Byte6:0, base-type=APPLICATION8, compu {phys=raw for raw 0..255}, transfer-property=PENDING
          signal ECU_Data_SymKey1_Byte7: start 63, 8 bit, big-endian, data-type-policy=OVERRIDE, init-value=Signal_ECU_Data_SymKey1_Byte7:0, base-type=APPLICATION8, compu {phys=raw for raw 0..255}, transfer-property=PENDING
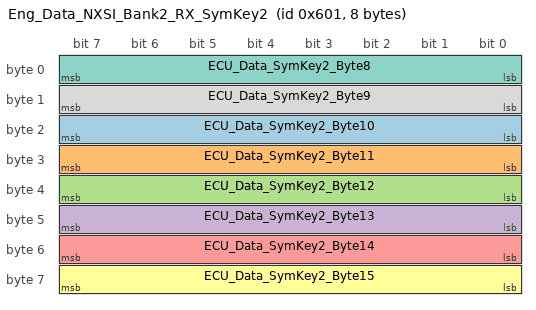
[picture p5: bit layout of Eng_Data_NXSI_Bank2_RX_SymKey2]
      frame Eng_Data_NXSI_Bank2_RX_SymKey2: id 0x601, from ECM, frame-length=8, can-addressing-mode=STANDARD, can-fd-frame-support=false, can-frame-rx-behavior=CAN-20, can-frame-tx-behavior=CAN-20
        carries pdu Eng_Data_NXSI_Bank2_RX_SymKey2: packing-byte-order=big-endian, start-position=7
        pdu Eng_Data_NXSI_Bank2_RX_SymKey2: length=8, unused-bit-pattern=0
          signal ECU_Data_SymKey2_Byte10: start 23, 8 bit, big-endian, data-type-policy=OVERRIDE, init-value=Signal_ECU_Data_SymKey2_Byte10:0, base-type=APPLICATION8, compu {phys=raw for raw 0..255}, transfer-property=PENDING
          signal ECU_Data_SymKey2_Byte11: start 31, 8 bit, big-endian, data-type-policy=OVERRIDE, init-value=Signal_ECU_Data_SymKey2_Byte11:0, base-type=APPLICATION8, compu {phys=raw for raw 0..255}, transfer-property=PENDING
          signal ECU_Data_SymKey2_Byte12: start 39, 8 bit, big-endian, data-type-policy=OVERRIDE, init-value=Signal_ECU_Data_SymKey2_Byte12:0, base-type=APPLICATION8, compu {phys=raw for raw 0..255}, transfer-property=PENDING
          signal ECU_Data_SymKey2_Byte13: start 47, 8 bit, big-endian, data-type-policy=OVERRIDE, init-value=Signal_ECU_Data_SymKey2_Byte13:0, base-type=APPLICATION8, compu {phys=raw for raw 0..255}, transfer-property=PENDING
          signal ECU_Data_SymKey2_Byte14: start 55, 8 bit, big-endian, data-type-policy=OVERRIDE, init-value=Signal_ECU_Data_SymKey2_Byte14:0, base-type=APPLICATION8, compu {phys=raw for raw 0..255}, transfer-property=PENDING
          signal ECU_Data_SymKey2_Byte15: start 63, 8 bit, big-endian, data-type-policy=OVERRIDE, init-value=Signal_ECU_Data_SymKey2_Byte15:0, base-type=APPLICATION8, compu {phys=raw for raw 0..255}, transfer-property=PENDING
          signal ECU_Data_SymKey2_Byte8: start 7, 8 bit, big-endian, data-type-policy=OVERRIDE, init-value=Signal_ECU_Data_SymKey2_Byte8:0, base-type=APPLICATION8, compu {phys=raw for raw 0..255}, transfer-property=PENDING
          signal ECU_Data_SymKey2_Byte9: start 15, 8 bit, big-endian, data-type-policy=OVERRIDE, init-value=Signal_ECU_Data_SymKey2_Byte9:0, base-type=APPLICATION8, compu {phys=raw for raw 0..255}, transfer-property=PENDING
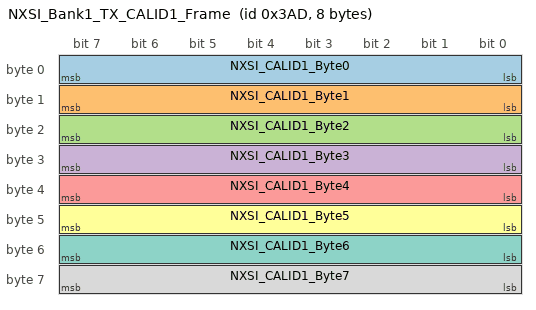
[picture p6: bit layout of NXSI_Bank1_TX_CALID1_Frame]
      frame NXSI_Bank1_TX_CALID1_Frame: id 0x3AD, to ECM, frame-length=8, can-addressing-mode=STANDARD, can-fd-frame-support=false, can-frame-rx-behavior=CAN-20, can-frame-tx-behavior=CAN-20
        carries pdu NXSI_Bank1_TX_CALID1_Frame: packing-byte-order=big-endian, start-position=7
        pdu NXSI_Bank1_TX_CALID1_Frame: length=8, transmission-mode-true-timing=cyclic-timing=time-period=1, unused-bit-pattern=0
          signal NXSI_CALID1_Byte0: start 7, 8 bit, big-endian, data-type-policy=OVERRIDE, init-value=Signal_NXSI_CALID1_Byte0:0, base-type=APPLICATION8, compu {phys=raw for raw 0..255}, transfer-property=PENDING, to ECM
          signal NXSI_CALID1_Byte1: start 15, 8 bit, big-endian, data-type-policy=OVERRIDE, init-value=Signal_NXSI_CALID1_Byte1:0, base-type=APPLICATION8, compu {phys=raw for raw 0..255}, transfer-property=PENDING, to ECM
          signal NXSI_CALID1_Byte2: start 23, 8 bit, big-endian, data-type-policy=OVERRIDE, init-value=Signal_NXSI_CALID1_Byte2:0, base-type=APPLICATION8, compu {phys=raw for raw 0..255}, transfer-property=PENDING, to ECM
          signal NXSI_CALID1_Byte3: start 31, 8 bit, big-endian, data-type-policy=OVERRIDE, init-value=Signal_NXSI_CALID1_Byte3:0, base-type=APPLICATION8, compu {phys=raw for raw 0..255}, transfer-property=PENDING, to ECM
          signal NXSI_CALID1_Byte4: start 39, 8 bit, big-endian, data-type-policy=OVERRIDE, init-value=Signal_NXSI_CALID1_Byte4:0, base-type=APPLICATION8, compu {phys=raw for raw 0..255}, transfer-property=PENDING, to ECM
          signal NXSI_CALID1_Byte5: start 47, 8 bit, big-endian, data-type-policy=OVERRIDE, init-value=Signal_NXSI_CALID1_Byte5:0, base-type=APPLICATION8, compu {phys=raw for raw 0..255}, transfer-property=PENDING, to ECM
          signal NXSI_CALID1_Byte6: start 55, 8 bit, big-endian, data-type-policy=OVERRIDE, init-value=Signal_NXSI_CALID1_Byte6:0, base-type=APPLICATION8, compu {phys=raw for raw 0..255}, transfer-property=PENDING, to ECM
          signal NXSI_CALID1_Byte7: start 63, 8 bit, big-endian, data-type-policy=OVERRIDE, init-value=Signal_NXSI_CALID1_Byte7:0, base-type=APPLICATION8, compu {phys=raw for raw 0..255}, transfer-property=PENDING, to ECM
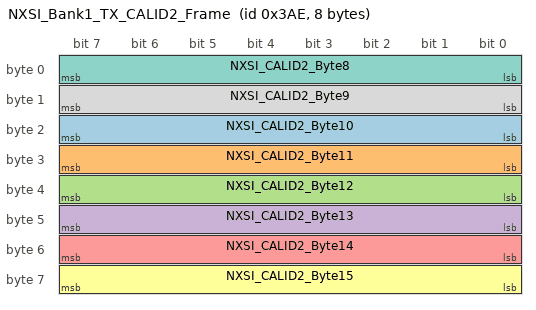
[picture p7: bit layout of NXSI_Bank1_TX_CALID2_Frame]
      frame NXSI_Bank1_TX_CALID2_Frame: id 0x3AE, to ECM, frame-length=8, can-addressing-mode=STANDARD, can-fd-frame-support=false, can-frame-rx-behavior=CAN-20, can-frame-tx-behavior=CAN-20
        carries pdu NXSI_Bank1_TX_CALID2_Frame: packing-byte-order=big-endian, start-position=7
        pdu NXSI_Bank1_TX_CALID2_Frame: length=8, transmission-mode-true-timing=cyclic-timing=time-period=1, unused-bit-pattern=0
          signal NXSI_CALID2_Byte10: start 23, 8 bit, big-endian, data-type-policy=OVERRIDE, init-value=Signal_NXSI_CALID2_Byte10:0, base-type=APPLICATION8, compu {phys=raw for raw 0..255}, transfer-property=PENDING, to ECM
          signal NXSI_CALID2_Byte11: start 31, 8 bit, big-endian, data-type-policy=OVERRIDE, init-value=Signal_NXSI_CALID2_Byte11:0, base-type=APPLICATION8, compu {phys=raw for raw 0..255}, transfer-property=PENDING, to ECM
          signal NXSI_CALID2_Byte12: start 39, 8 bit, big-endian, data-type-policy=OVERRIDE, init-value=Signal_NXSI_CALID2_Byte12:0, base-type=APPLICATION8, compu {phys=raw for raw 0..255}, transfer-property=PENDING, to ECM
          signal NXSI_CALID2_Byte13: start 47, 8 bit, big-endian, data-type-policy=OVERRIDE, init-value=Signal_NXSI_CALID2_Byte13:0, base-type=APPLICATION8, compu {phys=raw for raw 0..255}, transfer-property=PENDING, to ECM
          signal NXSI_CALID2_Byte14: start 55, 8 bit, big-endian, data-type-policy=OVERRIDE, init-value=Signal_NXSI_CALID2_Byte14:0, base-type=APPLICATION8, compu {phys=raw for raw 0..255}, transfer-property=PENDING, to ECM
          signal NXSI_CALID2_Byte15: start 63, 8 bit, big-endian, data-type-policy=OVERRIDE, init-value=Signal_NXSI_CALID2_Byte15:0, base-type=APPLICATION8, compu {phys=raw for raw 0..255}, transfer-property=PENDING, to ECM
          signal NXSI_CALID2_Byte8: start 7, 8 bit, big-endian, data-type-policy=OVERRIDE, init-value=Signal_NXSI_CALID2_Byte8:0, base-type=APPLICATION8, compu {phys=raw for raw 0..255}, transfer-property=PENDING, to ECM
          signal NXSI_CALID2_Byte9: start 15, 8 bit, big-endian, data-type-policy=OVERRIDE, init-value=Signal_NXSI_CALID2_Byte9:0, base-type=APPLICATION8, compu {phys=raw for raw 0..255}, transfer-property=PENDING, to ECM
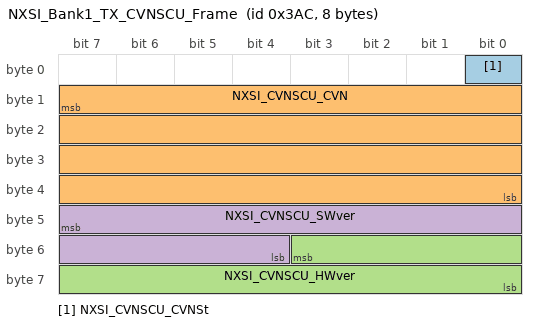
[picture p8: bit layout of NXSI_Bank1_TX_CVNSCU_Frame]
      frame NXSI_Bank1_TX_CVNSCU_Frame: id 0x3AC, to ECM, frame-length=8, can-addressing-mode=STANDARD, can-fd-frame-support=false, can-frame-rx-behavior=CAN-20, can-frame-tx-behavior=CAN-20
        carries pdu NXSI_Bank1_TX_CVNSCU_Frame: packing-byte-order=big-endian, start-position=7
        pdu NXSI_Bank1_TX_CVNSCU_Frame: length=8, transmission-mode-true-timing=cyclic-timing=time-period=1, unused-bit-pattern=0
          signal NXSI_CVNSCU_CVNSt: start 0, 1 bit, big-endian, data-type-policy=OVERRIDE, init-value=Signal_NXSI_CVNSCU_CVNSt:0, base-type=APPLICATION1, compu-method=DataTypeSemantics/NXSI_CVNSCU_CVNSt_COMPU, transfer-property=PENDING, to ECM
          signal NXSI_CVNSCU_CVN: start 15, 32 bit, big-endian, data-type-policy=OVERRIDE, init-value=Signal_NXSI_CVNSCU_CVN:0, base-type=APPLICATION32, compu {phys=raw for raw 0..2147483647}, transfer-property=PENDING, to ECM
          signal NXSI_CVNSCU_HWver: start 51, 12 bit, big-endian, data-type-policy=OVERRIDE, init-value=Signal_NXSI_CVNSCU_HWver:0, base-type=APPLICATION12, compu {phys=raw for raw 0..4095}, transfer-property=PENDING, to ECM
          signal NXSI_CVNSCU_SWver: start 47, 12 bit, big-endian, data-type-policy=OVERRIDE, init-value=Signal_NXSI_CVNSCU_SWver:0, base-type=APPLICATION12, compu {phys=raw for raw 0..4095}, transfer-property=PENDING, to ECM
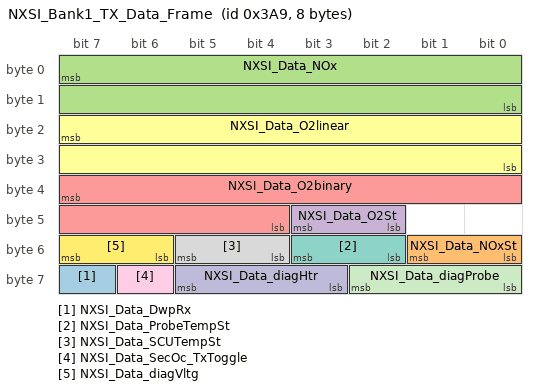
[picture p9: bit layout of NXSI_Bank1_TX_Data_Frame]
      frame NXSI_Bank1_TX_Data_Frame: id 0x3A9, to ECM, frame-length=8, can-addressing-mode=STANDARD, can-fd-frame-support=false, can-frame-rx-behavior=CAN-20, can-frame-tx-behavior=CAN-20
        carries pdu NXSI_Bank1_TX_Data_Frame: packing-byte-order=big-endian, start-position=7
        pdu NXSI_Bank1_TX_Data_Frame: length=8, transmission-mode-true-timing=cyclic-timing=time-period=0.01, unused-bit-pattern=0
          signal NXSI_Data_DwpRx: start 63, 1 bit, big-endian, data-type-policy=OVERRIDE, init-value=Signal_NXSI_Data_DwpRx:0, base-type=APPLICATION1, compu-method=DataTypeSemantics/NXSI_Data_DwpRx_COMPU, transfer-property=PENDING, to ECM
          signal NXSI_Data_NOxSt: start 49, 2 bit, big-endian, data-type-policy=OVERRIDE, init-value=Signal_NXSI_Data_NOxSt:0, base-type=APPLICATION2, compu-method=DataTypeSemantics/NXSI_Data_NOxSt_COMPU, transfer-property=PENDING, to ECM
          signal NXSI_Data_NOx: start 7, 16 bit, big-endian, data-type-policy=OVERRIDE, init-value=Signal_NXSI_Data_NOx:0, base-type=APPLICATION16, compu {phys=raw*0.05-200 for raw 0..65535; unit Unit_ppm}, transfer-property=PENDING, to ECM
          signal NXSI_Data_O2St: start 43, 2 bit, big-endian, data-type-policy=OVERRIDE, init-value=Signal_NXSI_Data_O2St:0, base-type=APPLICATION2, compu-method=DataTypeSemantics/NXSI_Data_O2St_COMPU, transfer-property=PENDING, to ECM
          signal NXSI_Data_O2binary: start 39, 12 bit, big-endian, data-type-policy=OVERRIDE, init-value=Signal_NXSI_Data_O2binary:0, base-type=APPLICATION12, compu {phys=raw*0.3152-100 for raw 0..4095; unit Unit_mV}, transfer-property=PENDING, to ECM
          signal NXSI_Data_O2linear: start 23, 16 bit, big-endian, data-type-policy=OVERRIDE, init-value=Signal_NXSI_Data_O2linear:0, base-type=APPLICATION16, compu {phys=raw*0.00061-10 for raw 0..65535; unit Unit_%}, transfer-property=PENDING, to ECM
          signal NXSI_Data_ProbeTempSt: start 51, 2 bit, big-endian, data-type-policy=OVERRIDE, init-value=Signal_NXSI_Data_ProbeTempSt:0, base-type=APPLICATION2, compu-method=DataTypeSemantics/NXSI_Data_ProbeTempSt_COMPU, transfer-property=PENDING, to ECM
          signal NXSI_Data_SCUTempSt: start 53, 2 bit, big-endian, data-type-policy=OVERRIDE, init-value=Signal_NXSI_Data_SCUTempSt:0, base-type=APPLICATION2, compu-method=DataTypeSemantics/NXSI_Data_SCUTempSt_COMPU, transfer-property=PENDING, to ECM
          signal NXSI_Data_SecOc_TxToggle: start 62, 1 bit, big-endian, data-type-policy=OVERRIDE, init-value=Signal_NXSI_Data_SecOc_TxToggle:0, base-type=APPLICATION1, compu-method=DataTypeSemantics/NXSI_Data_SecOc_TxToggle_COMPU, transfer-property=PENDING, to ECM
          signal NXSI_Data_diagHtr: start 61, 3 bit, big-endian, data-type-policy=OVERRIDE, init-value=Signal_NXSI_Data_diagHtr:0, base-type=APPLICATION3, compu-method=DataTypeSemantics/NXSI_Data_diagHtr_COMPU, transfer-property=PENDING, to ECM
          signal NXSI_Data_diagProbe: start 58, 3 bit, big-endian, data-type-policy=OVERRIDE, init-value=Signal_NXSI_Data_diagProbe:0, base-type=APPLICATION3, compu-method=DataTypeSemantics/NXSI_Data_diagProbe_COMPU, transfer-property=PENDING, to ECM
          signal NXSI_Data_diagVltg: start 55, 2 bit, big-endian, data-type-policy=OVERRIDE, init-value=Signal_NXSI_Data_diagVltg:0, base-type=APPLICATION2, compu-method=DataTypeSemantics/NXSI_Data_diagVltg_COMPU, transfer-property=PENDING, to ECM
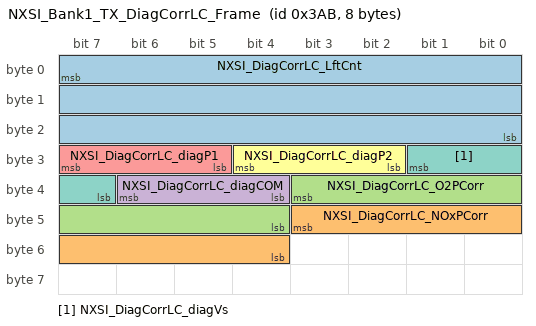
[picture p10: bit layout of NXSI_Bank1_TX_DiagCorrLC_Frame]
      frame NXSI_Bank1_TX_DiagCorrLC_Frame: id 0x3AB, to ECM, frame-length=8, can-addressing-mode=STANDARD, can-fd-frame-support=false, can-frame-rx-behavior=CAN-20, can-frame-tx-behavior=CAN-20
        carries pdu NXSI_Bank1_TX_DiagCorrLC_Frame: packing-byte-order=big-endian, start-position=7
        pdu NXSI_Bank1_TX_DiagCorrLC_Frame: length=8, transmission-mode-true-timing=cyclic-timing=time-period=0.1, unused-bit-pattern=0
          signal NXSI_DiagCorrLC_LftCnt: start 7, 24 bit, big-endian, data-type-policy=OVERRIDE, init-value=Signal_NXSI_DiagCorrLC_LftCnt:0, base-type=APPLICATION24, compu {phys=raw for raw 0..16777215; unit Unit_min}, transfer-property=PENDING, to ECM
          signal NXSI_DiagCorrLC_NOxPCorr: start 43, 8 bit, big-endian, data-type-policy=OVERRIDE, init-value=Signal_NXSI_DiagCorrLC_NOxPCorr:0, base-type=APPLICATION8, compu {phys=raw*0.005 for raw 0..255}, transfer-property=PENDING, to ECM
          signal NXSI_DiagCorrLC_O2PCorr: start 35, 8 bit, big-endian, data-type-policy=OVERRIDE, init-value=Signal_NXSI_DiagCorrLC_O2PCorr:0, base-type=APPLICATION8, compu {phys=raw*0.005 for raw 0..255}, transfer-property=PENDING, to ECM
          signal NXSI_DiagCorrLC_diagCOM: start 38, 3 bit, big-endian, data-type-policy=OVERRIDE, init-value=Signal_NXSI_DiagCorrLC_diagCOM:0, base-type=APPLICATION3, compu-method=DataTypeSemantics/NXSI_DiagCorrLC_diagCOM_COMPU, transfer-property=PENDING, to ECM
          signal NXSI_DiagCorrLC_diagP1: start 31, 3 bit, big-endian, data-type-policy=OVERRIDE, init-value=Signal_NXSI_DiagCorrLC_diagP1:0, base-type=APPLICATION3, compu-method=DataTypeSemantics/NXSI_DiagCorrLC_diagP1_COMPU, transfer-property=PENDING, to ECM
          signal NXSI_DiagCorrLC_diagP2: start 28, 3 bit, big-endian, data-type-policy=OVERRIDE, init-value=Signal_NXSI_DiagCorrLC_diagP2:0, base-type=APPLICATION3, compu-method=DataTypeSemantics/NXSI_DiagCorrLC_diagP2_COMPU, transfer-property=PENDING, to ECM
          signal NXSI_DiagCorrLC_diagVs: start 25, 3 bit, big-endian, data-type-policy=OVERRIDE, init-value=Signal_NXSI_DiagCorrLC_diagVs:0, base-type=APPLICATION3, compu-method=DataTypeSemantics/NXSI_DiagCorrLC_diagVs_COMPU, transfer-property=PENDING, to ECM
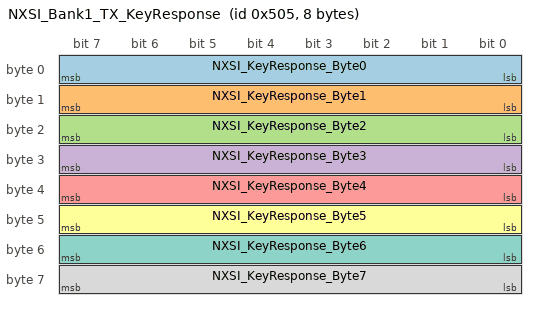
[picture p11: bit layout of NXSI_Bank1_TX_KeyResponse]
      frame NXSI_Bank1_TX_KeyResponse: id 0x505, to ECM, frame-length=8, can-addressing-mode=STANDARD, can-fd-frame-support=false, can-frame-rx-behavior=CAN-20, can-frame-tx-behavior=CAN-20
        carries pdu NXSI_Bank1_TX_KeyResponse: packing-byte-order=big-endian, start-position=7
        pdu NXSI_Bank1_TX_KeyResponse: length=8, unused-bit-pattern=0
          signal NXSI_KeyResponse_Byte0: start 7, 8 bit, big-endian, data-type-policy=OVERRIDE, init-value=Signal_NXSI_KeyResponse_Byte0:0, base-type=APPLICATION8, compu-method=DataTypeSemantics/NXSI_KeyResponse_Byte0_COMPU, transfer-property=PENDING, to ECM
          signal NXSI_KeyResponse_Byte1: start 15, 8 bit, big-endian, data-type-policy=OVERRIDE, init-value=Signal_NXSI_KeyResponse_Byte1:0, base-type=APPLICATION8, compu {phys=raw for raw 0..255}, transfer-property=PENDING, to ECM
          signal NXSI_KeyResponse_Byte2: start 23, 8 bit, big-endian, data-type-policy=OVERRIDE, init-value=Signal_NXSI_KeyResponse_Byte2:0, base-type=APPLICATION8, compu {phys=raw for raw 0..255}, transfer-property=PENDING, to ECM
          signal NXSI_KeyResponse_Byte3: start 31, 8 bit, big-endian, data-type-policy=OVERRIDE, init-value=Signal_NXSI_KeyResponse_Byte3:0, base-type=APPLICATION8, compu {phys=raw for raw 0..255}, transfer-property=PENDING, to ECM
          signal NXSI_KeyResponse_Byte4: start 39, 8 bit, big-endian, data-type-policy=OVERRIDE, init-value=Signal_NXSI_KeyResponse_Byte4:0, base-type=APPLICATION8, compu {phys=raw for raw 0..255}, transfer-property=PENDING, to ECM
          signal NXSI_KeyResponse_Byte5: start 47, 8 bit, big-endian, data-type-policy=OVERRIDE, init-value=Signal_NXSI_KeyResponse_Byte5:0, base-type=APPLICATION8, compu {phys=raw for raw 0..255}, transfer-property=PENDING, to ECM
          signal NXSI_KeyResponse_Byte6: start 55, 8 bit, big-endian, data-type-policy=OVERRIDE, init-value=Signal_NXSI_KeyResponse_Byte6:0, base-type=APPLICATION8, compu {phys=raw for raw 0..255}, transfer-property=PENDING, to ECM
          signal NXSI_KeyResponse_Byte7: start 63, 8 bit, big-endian, data-type-policy=OVERRIDE, init-value=Signal_NXSI_KeyResponse_Byte7:0, base-type=APPLICATION8, compu {phys=raw for raw 0..255}, transfer-property=PENDING, to ECM
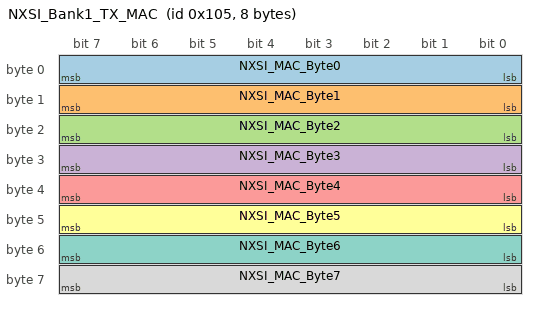
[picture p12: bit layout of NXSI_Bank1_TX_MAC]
      frame NXSI_Bank1_TX_MAC: id 0x105, to ECM, frame-length=8, can-addressing-mode=STANDARD, can-fd-frame-support=false, can-frame-rx-behavior=CAN-20, can-frame-tx-behavior=CAN-20
        carries pdu NXSI_Bank1_TX_MAC: packing-byte-order=big-endian, start-position=7
        pdu NXSI_Bank1_TX_MAC: length=8, unused-bit-pattern=0
          signal NXSI_MAC_Byte0: start 7, 8 bit, big-endian, data-type-policy=OVERRIDE, init-value=Signal_NXSI_MAC_Byte0:0, base-type=APPLICATION8, compu {phys=raw for raw 0..255}, transfer-property=PENDING, to ECM
          signal NXSI_MAC_Byte1: start 15, 8 bit, big-endian, data-type-policy=OVERRIDE, init-value=Signal_NXSI_MAC_Byte1:0, base-type=APPLICATION8, compu {phys=raw for raw 0..255}, transfer-property=PENDING, to ECM
          signal NXSI_MAC_Byte2: start 23, 8 bit, big-endian, data-type-policy=OVERRIDE, init-value=Signal_NXSI_MAC_Byte2:0, base-type=APPLICATION8, compu {phys=raw for raw 0..255}, transfer-property=PENDING, to ECM
          signal NXSI_MAC_Byte3: start 31, 8 bit, big-endian, data-type-policy=OVERRIDE, init-value=Signal_NXSI_MAC_Byte3:0, base-type=APPLICATION8, compu {phys=raw for raw 0..255}, transfer-property=PENDING, to ECM
          signal NXSI_MAC_Byte4: start 39, 8 bit, big-endian, data-type-policy=OVERRIDE, init-value=Signal_NXSI_MAC_Byte4:0, base-type=APPLICATION8, compu {phys=raw for raw 0..255}, transfer-property=PENDING, to ECM
          signal NXSI_MAC_Byte5: start 47, 8 bit, big-endian, data-type-policy=OVERRIDE, init-value=Signal_NXSI_MAC_Byte5:0, base-type=APPLICATION8, compu {phys=raw for raw 0..255}, transfer-property=PENDING, to ECM
          signal NXSI_MAC_Byte6: start 55, 8 bit, big-endian, data-type-policy=OVERRIDE, init-value=Signal_NXSI_MAC_Byte6:0, base-type=APPLICATION8, compu {phys=raw for raw 0..255}, transfer-property=PENDING, to ECM
          signal NXSI_MAC_Byte7: start 63, 8 bit, big-endian, data-type-policy=OVERRIDE, init-value=Signal_NXSI_MAC_Byte7:0, base-type=APPLICATION8, compu {phys=raw for raw 0..255}, transfer-property=PENDING, to ECM
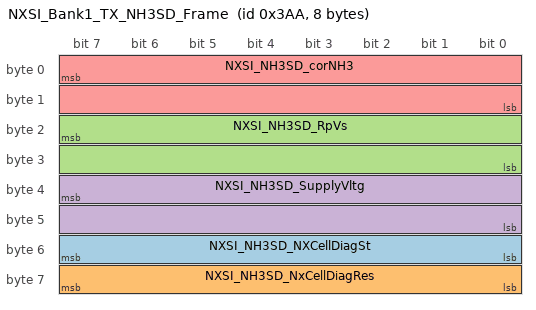
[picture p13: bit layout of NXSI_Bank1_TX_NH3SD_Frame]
      frame NXSI_Bank1_TX_NH3SD_Frame: id 0x3AA, to ECM, frame-length=8, can-addressing-mode=STANDARD, can-fd-frame-support=false, can-frame-rx-behavior=CAN-20, can-frame-tx-behavior=CAN-20
        carries pdu NXSI_Bank1_TX_NH3SD_Frame: packing-byte-order=big-endian, start-position=7
        pdu NXSI_Bank1_TX_NH3SD_Frame: length=8, transmission-mode-true-timing=cyclic-timing=time-period=0.01, unused-bit-pattern=0
          signal NXSI_NH3SD_NXCellDiagSt: start 55, 8 bit, big-endian, data-type-policy=OVERRIDE, init-value=Signal_NXSI_NH3SD_NXCellDiagSt:0, base-type=APPLICATION8, compu-method=DataTypeSemantics/NXSI_NH3SD_NXCellDiagSt_COMPU, transfer-property=PENDING, to ECM
          signal NXSI_NH3SD_NxCellDiagRes: start 63, 8 bit, big-endian, data-type-policy=OVERRIDE, init-value=Signal_NXSI_NH3SD_NxCellDiagRes:0, base-type=APPLICATION8, compu {phys=raw for raw 0..255; unit Unit_%}, transfer-property=PENDING, to ECM
          signal NXSI_NH3SD_RpVs: start 23, 16 bit, big-endian, data-type-policy=OVERRIDE, init-value=Signal_NXSI_NH3SD_RpVs:0, base-type=APPLICATION16, compu {phys=raw*0.01 for raw 0..65535; unit Unit_Ohm}, transfer-property=PENDING, to ECM
          signal NXSI_NH3SD_SupplyVltg: start 39, 16 bit, big-endian, data-type-policy=OVERRIDE, init-value=Signal_NXSI_NH3SD_SupplyVltg:0, base-type=APPLICATION16, compu {phys=raw*0.5 for raw 0..65535; unit Unit_mV}, transfer-property=PENDING, to ECM
          signal NXSI_NH3SD_corNH3: start 7, 16 bit, big-endian, data-type-policy=OVERRIDE, init-value=Signal_NXSI_NH3SD_corNH3:0, base-type=APPLICATION16, compu {phys=raw*0.005 for raw 0..65535}, transfer-property=PENDING, to ECM
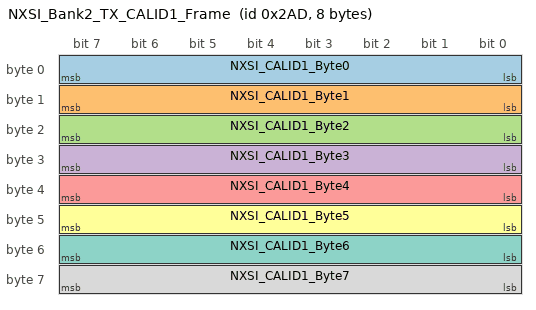
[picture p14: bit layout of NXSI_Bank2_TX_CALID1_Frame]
      frame NXSI_Bank2_TX_CALID1_Frame: id 0x2AD, to ECM, frame-length=8, can-addressing-mode=STANDARD, can-fd-frame-support=false, can-frame-rx-behavior=CAN-20, can-frame-tx-behavior=CAN-20
        carries pdu NXSI_Bank2_TX_CALID1_Frame: packing-byte-order=big-endian, start-position=7
        pdu NXSI_Bank2_TX_CALID1_Frame: length=8, transmission-mode-true-timing=cyclic-timing=time-period=1, unused-bit-pattern=0
          signal NXSI_CALID1_Byte0: start 7, 8 bit, big-endian, data-type-policy=OVERRIDE, init-value=Signal_NXSI_CALID1_Byte0:0, base-type=APPLICATION8, compu {phys=raw for raw 0..255}, transfer-property=PENDING, to ECM
          signal NXSI_CALID1_Byte1: start 15, 8 bit, big-endian, data-type-policy=OVERRIDE, init-value=Signal_NXSI_CALID1_Byte1:0, base-type=APPLICATION8, compu {phys=raw for raw 0..255}, transfer-property=PENDING, to ECM
          signal NXSI_CALID1_Byte2: start 23, 8 bit, big-endian, data-type-policy=OVERRIDE, init-value=Signal_NXSI_CALID1_Byte2:0, base-type=APPLICATION8, compu {phys=raw for raw 0..255}, transfer-property=PENDING, to ECM
          signal NXSI_CALID1_Byte3: start 31, 8 bit, big-endian, data-type-policy=OVERRIDE, init-value=Signal_NXSI_CALID1_Byte3:0, base-type=APPLICATION8, compu {phys=raw for raw 0..255}, transfer-property=PENDING, to ECM
          signal NXSI_CALID1_Byte4: start 39, 8 bit, big-endian, data-type-policy=OVERRIDE, init-value=Signal_NXSI_CALID1_Byte4:0, base-type=APPLICATION8, compu {phys=raw for raw 0..255}, transfer-property=PENDING, to ECM
          signal NXSI_CALID1_Byte5: start 47, 8 bit, big-endian, data-type-policy=OVERRIDE, init-value=Signal_NXSI_CALID1_Byte5:0, base-type=APPLICATION8, compu {phys=raw for raw 0..255}, transfer-property=PENDING, to ECM
          signal NXSI_CALID1_Byte6: start 55, 8 bit, big-endian, data-type-policy=OVERRIDE, init-value=Signal_NXSI_CALID1_Byte6:0, base-type=APPLICATION8, compu {phys=raw for raw 0..255}, transfer-property=PENDING, to ECM
          signal NXSI_CALID1_Byte7: start 63, 8 bit, big-endian, data-type-policy=OVERRIDE, init-value=Signal_NXSI_CALID1_Byte7:0, base-type=APPLICATION8, compu {phys=raw for raw 0..255}, transfer-property=PENDING, to ECM
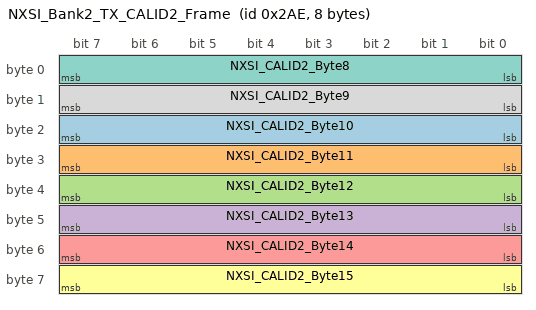
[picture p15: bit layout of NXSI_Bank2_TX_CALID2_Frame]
      frame NXSI_Bank2_TX_CALID2_Frame: id 0x2AE, to ECM, frame-length=8, can-addressing-mode=STANDARD, can-fd-frame-support=false, can-frame-rx-behavior=CAN-20, can-frame-tx-behavior=CAN-20
        carries pdu NXSI_Bank2_TX_CALID2_Frame: packing-byte-order=big-endian, start-position=7
        pdu NXSI_Bank2_TX_CALID2_Frame: length=8, transmission-mode-true-timing=cyclic-timing=time-period=1, unused-bit-pattern=0
          signal NXSI_CALID2_Byte10: start 23, 8 bit, big-endian, data-type-policy=OVERRIDE, init-value=Signal_NXSI_CALID2_Byte10:0, base-type=APPLICATION8, compu {phys=raw for raw 0..255}, transfer-property=PENDING, to ECM
          signal NXSI_CALID2_Byte11: start 31, 8 bit, big-endian, data-type-policy=OVERRIDE, init-value=Signal_NXSI_CALID2_Byte11:0, base-type=APPLICATION8, compu {phys=raw for raw 0..255}, transfer-property=PENDING, to ECM
          signal NXSI_CALID2_Byte12: start 39, 8 bit, big-endian, data-type-policy=OVERRIDE, init-value=Signal_NXSI_CALID2_Byte12:0, base-type=APPLICATION8, compu {phys=raw for raw 0..255}, transfer-property=PENDING, to ECM
          signal NXSI_CALID2_Byte13: start 47, 8 bit, big-endian, data-type-policy=OVERRIDE, init-value=Signal_NXSI_CALID2_Byte13:0, base-type=APPLICATION8, compu {phys=raw for raw 0..255}, transfer-property=PENDING, to ECM
          signal NXSI_CALID2_Byte14: start 55, 8 bit, big-endian, data-type-policy=OVERRIDE, init-value=Signal_NXSI_CALID2_Byte14:0, base-type=APPLICATION8, compu {phys=raw for raw 0..255}, transfer-property=PENDING, to ECM
          signal NXSI_CALID2_Byte15: start 63, 8 bit, big-endian, data-type-policy=OVERRIDE, init-value=Signal_NXSI_CALID2_Byte15:0, base-type=APPLICATION8, compu {phys=raw for raw 0..255}, transfer-property=PENDING, to ECM
          signal NXSI_CALID2_Byte8: start 7, 8 bit, big-endian, data-type-policy=OVERRIDE, init-value=Signal_NXSI_CALID2_Byte8:0, base-type=APPLICATION8, compu {phys=raw for raw 0..255}, transfer-property=PENDING, to ECM
          signal NXSI_CALID2_Byte9: start 15, 8 bit, big-endian, data-type-policy=OVERRIDE, init-value=Signal_NXSI_CALID2_Byte9:0, base-type=APPLICATION8, compu {phys=raw for raw 0..255}, transfer-property=PENDING, to ECM
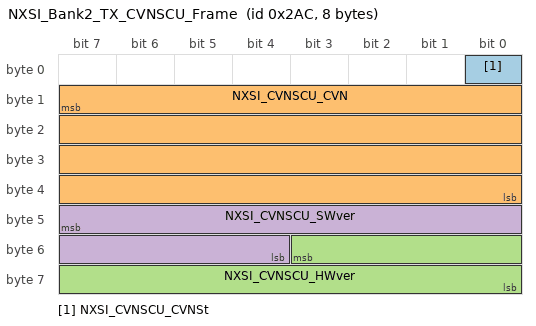
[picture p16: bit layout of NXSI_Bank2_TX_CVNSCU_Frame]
      frame NXSI_Bank2_TX_CVNSCU_Frame: id 0x2AC, to ECM, frame-length=8, can-addressing-mode=STANDARD, can-fd-frame-support=false, can-frame-rx-behavior=CAN-20, can-frame-tx-behavior=CAN-20
        carries pdu NXSI_Bank2_TX_CVNSCU_Frame: packing-byte-order=big-endian, start-position=7
        pdu NXSI_Bank2_TX_CVNSCU_Frame: length=8, transmission-mode-true-timing=cyclic-timing=time-period=1, unused-bit-pattern=0
          signal NXSI_CVNSCU_CVNSt: start 0, 1 bit, big-endian, data-type-policy=OVERRIDE, init-value=Signal_NXSI_CVNSCU_CVNSt:0, base-type=APPLICATION1, compu-method=DataTypeSemantics/NXSI_CVNSCU_CVNSt_COMPU, transfer-property=PENDING, to ECM
          signal NXSI_CVNSCU_CVN: start 15, 32 bit, big-endian, data-type-policy=OVERRIDE, init-value=Signal_NXSI_CVNSCU_CVN:0, base-type=APPLICATION32, compu {phys=raw for raw 0..2147483647}, transfer-property=PENDING, to ECM
          signal NXSI_CVNSCU_HWver: start 51, 12 bit, big-endian, data-type-policy=OVERRIDE, init-value=Signal_NXSI_CVNSCU_HWver:0, base-type=APPLICATION12, compu {phys=raw for raw 0..4095}, transfer-property=PENDING, to ECM
          signal NXSI_CVNSCU_SWver: start 47, 12 bit, big-endian, data-type-policy=OVERRIDE, init-value=Signal_NXSI_CVNSCU_SWver:0, base-type=APPLICATION12, compu {phys=raw for raw 0..4095}, transfer-property=PENDING, to ECM
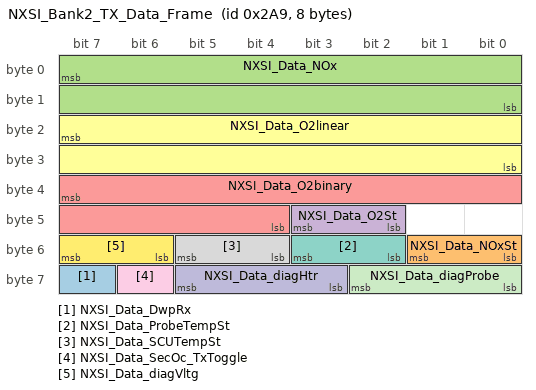
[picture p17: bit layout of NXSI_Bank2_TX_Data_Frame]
      frame NXSI_Bank2_TX_Data_Frame: id 0x2A9, to ECM, frame-length=8, can-addressing-mode=STANDARD, can-fd-frame-support=false, can-frame-rx-behavior=CAN-20, can-frame-tx-behavior=CAN-20
        carries pdu NXSI_Bank2_TX_Data_Frame: packing-byte-order=big-endian, start-position=7
        pdu NXSI_Bank2_TX_Data_Frame: length=8, transmission-mode-true-timing=cyclic-timing=time-period=0.01, unused-bit-pattern=0
          signal NXSI_Data_DwpRx: start 63, 1 bit, big-endian, data-type-policy=OVERRIDE, init-value=Signal_NXSI_Data_DwpRx:0, base-type=APPLICATION1, compu-method=DataTypeSemantics/NXSI_Data_DwpRx_COMPU, transfer-property=PENDING, to ECM
          signal NXSI_Data_NOxSt: start 49, 2 bit, big-endian, data-type-policy=OVERRIDE, init-value=Signal_NXSI_Data_NOxSt:0, base-type=APPLICATION2, compu-method=DataTypeSemantics/NXSI_Data_NOxSt_COMPU, transfer-property=PENDING, to ECM
          signal NXSI_Data_NOx: start 7, 16 bit, big-endian, data-type-policy=OVERRIDE, init-value=Signal_NXSI_Data_NOx:0, base-type=APPLICATION16, compu {phys=raw*0.05-200 for raw 0..65535; unit Unit_ppm}, transfer-property=PENDING, to ECM
          signal NXSI_Data_O2St: start 43, 2 bit, big-endian, data-type-policy=OVERRIDE, init-value=Signal_NXSI_Data_O2St:0, base-type=APPLICATION2, compu-method=DataTypeSemantics/NXSI_Data_O2St_COMPU, transfer-property=PENDING, to ECM
          signal NXSI_Data_O2binary: start 39, 12 bit, big-endian, data-type-policy=OVERRIDE, init-value=Signal_NXSI_Data_O2binary:0, base-type=APPLICATION12, compu {phys=raw*0.3152-100 for raw 0..4095; unit Unit_mV}, transfer-property=PENDING, to ECM
          signal NXSI_Data_O2linear: start 23, 16 bit, big-endian, data-type-policy=OVERRIDE, init-value=Signal_NXSI_Data_O2linear:0, base-type=APPLICATION16, compu {phys=raw*0.00061-10 for raw 0..65535; unit Unit_%}, transfer-property=PENDING, to ECM
          signal NXSI_Data_ProbeTempSt: start 51, 2 bit, big-endian, data-type-policy=OVERRIDE, init-value=Signal_NXSI_Data_ProbeTempSt:0, base-type=APPLICATION2, compu-method=DataTypeSemantics/NXSI_Data_ProbeTempSt_COMPU, transfer-property=PENDING, to ECM
          signal NXSI_Data_SCUTempSt: start 53, 2 bit, big-endian, data-type-policy=OVERRIDE, init-value=Signal_NXSI_Data_SCUTempSt:0, base-type=APPLICATION2, compu-method=DataTypeSemantics/NXSI_Data_SCUTempSt_COMPU, transfer-property=PENDING, to ECM
          signal NXSI_Data_SecOc_TxToggle: start 62, 1 bit, big-endian, data-type-policy=OVERRIDE, init-value=Signal_NXSI_Data_SecOc_TxToggle:0, base-type=APPLICATION1, compu-method=DataTypeSemantics/NXSI_Data_SecOc_TxToggle_COMPU, transfer-property=PENDING, to ECM
          signal NXSI_Data_diagHtr: start 61, 3 bit, big-endian, data-type-policy=OVERRIDE, init-value=Signal_NXSI_Data_diagHtr:0, base-type=APPLICATION3, compu-method=DataTypeSemantics/NXSI_Data_diagHtr_COMPU, transfer-property=PENDING, to ECM
          signal NXSI_Data_diagProbe: start 58, 3 bit, big-endian, data-type-policy=OVERRIDE, init-value=Signal_NXSI_Data_diagProbe:0, base-type=APPLICATION3, compu-method=DataTypeSemantics/NXSI_Data_diagProbe_COMPU, transfer-property=PENDING, to ECM
          signal NXSI_Data_diagVltg: start 55, 2 bit, big-endian, data-type-policy=OVERRIDE, init-value=Signal_NXSI_Data_diagVltg:0, base-type=APPLICATION2, compu-method=DataTypeSemantics/NXSI_Data_diagVltg_COMPU, transfer-property=PENDING, to ECM
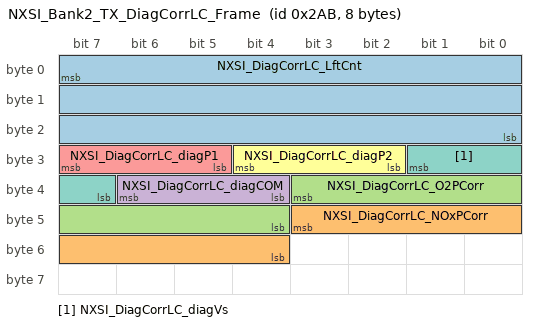
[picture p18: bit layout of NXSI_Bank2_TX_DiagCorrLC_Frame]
      frame NXSI_Bank2_TX_DiagCorrLC_Frame: id 0x2AB, to ECM, frame-length=8, can-addressing-mode=STANDARD, can-fd-frame-support=false, can-frame-rx-behavior=CAN-20, can-frame-tx-behavior=CAN-20
        carries pdu NXSI_Bank2_TX_DiagCorrLC_Frame: packing-byte-order=big-endian, start-position=7
        pdu NXSI_Bank2_TX_DiagCorrLC_Frame: length=8, transmission-mode-true-timing=cyclic-timing=time-period=0.1, unused-bit-pattern=0
          signal NXSI_DiagCorrLC_LftCnt: start 7, 24 bit, big-endian, data-type-policy=OVERRIDE, init-value=Signal_NXSI_DiagCorrLC_LftCnt:0, base-type=APPLICATION24, compu {phys=raw for raw 0..16777215; unit Unit_min}, transfer-property=PENDING, to ECM
          signal NXSI_DiagCorrLC_NOxPCorr: start 43, 8 bit, big-endian, data-type-policy=OVERRIDE, init-value=Signal_NXSI_DiagCorrLC_NOxPCorr:0, base-type=APPLICATION8, compu {phys=raw*0.005 for raw 0..255}, transfer-property=PENDING, to ECM
          signal NXSI_DiagCorrLC_O2PCorr: start 35, 8 bit, big-endian, data-type-policy=OVERRIDE, init-value=Signal_NXSI_DiagCorrLC_O2PCorr:0, base-type=APPLICATION8, compu {phys=raw*0.005 for raw 0..255}, transfer-property=PENDING, to ECM
          signal NXSI_DiagCorrLC_diagCOM: start 38, 3 bit, big-endian, data-type-policy=OVERRIDE, init-value=Signal_NXSI_DiagCorrLC_diagCOM:0, base-type=APPLICATION3, compu-method=DataTypeSemantics/NXSI_DiagCorrLC_diagCOM_COMPU, transfer-property=PENDING, to ECM
          signal NXSI_DiagCorrLC_diagP1: start 31, 3 bit, big-endian, data-type-policy=OVERRIDE, init-value=Signal_NXSI_DiagCorrLC_diagP1:0, base-type=APPLICATION3, compu-method=DataTypeSemantics/NXSI_DiagCorrLC_diagP1_COMPU, transfer-property=PENDING, to ECM
          signal NXSI_DiagCorrLC_diagP2: start 28, 3 bit, big-endian, data-type-policy=OVERRIDE, init-value=Signal_NXSI_DiagCorrLC_diagP2:0, base-type=APPLICATION3, compu-method=DataTypeSemantics/NXSI_DiagCorrLC_diagP2_COMPU, transfer-property=PENDING, to ECM
          signal NXSI_DiagCorrLC_diagVs: start 25, 3 bit, big-endian, data-type-policy=OVERRIDE, init-value=Signal_NXSI_DiagCorrLC_diagVs:0, base-type=APPLICATION3, compu-method=DataTypeSemantics/NXSI_DiagCorrLC_diagVs_COMPU, transfer-property=PENDING, to ECM
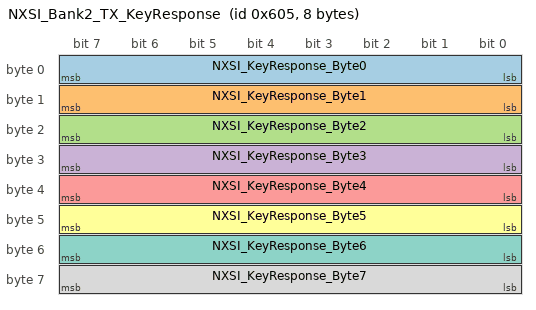
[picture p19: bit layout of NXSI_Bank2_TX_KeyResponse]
      frame NXSI_Bank2_TX_KeyResponse: id 0x605, to ECM, frame-length=8, can-addressing-mode=STANDARD, can-fd-frame-support=false, can-frame-rx-behavior=CAN-20, can-frame-tx-behavior=CAN-20
        carries pdu NXSI_Bank2_TX_KeyResponse: packing-byte-order=big-endian, start-position=7
        pdu NXSI_Bank2_TX_KeyResponse: length=8, unused-bit-pattern=0
          signal NXSI_KeyResponse_Byte0: start 7, 8 bit, big-endian, data-type-policy=OVERRIDE, init-value=Signal_NXSI_KeyResponse_Byte0:0, base-type=APPLICATION8, compu-method=DataTypeSemantics/NXSI_KeyResponse_Byte0_COMPU, transfer-property=PENDING, to ECM
          signal NXSI_KeyResponse_Byte1: start 15, 8 bit, big-endian, data-type-policy=OVERRIDE, init-value=Signal_NXSI_KeyResponse_Byte1:0, base-type=APPLICATION8, compu {phys=raw for raw 0..255}, transfer-property=PENDING, to ECM
          signal NXSI_KeyResponse_Byte2: start 23, 8 bit, big-endian, data-type-policy=OVERRIDE, init-value=Signal_NXSI_KeyResponse_Byte2:0, base-type=APPLICATION8, compu {phys=raw for raw 0..255}, transfer-property=PENDING, to ECM
          signal NXSI_KeyResponse_Byte3: start 31, 8 bit, big-endian, data-type-policy=OVERRIDE, init-value=Signal_NXSI_KeyResponse_Byte3:0, base-type=APPLICATION8, compu {phys=raw for raw 0..255}, transfer-property=PENDING, to ECM
          signal NXSI_KeyResponse_Byte4: start 39, 8 bit, big-endian, data-type-policy=OVERRIDE, init-value=Signal_NXSI_KeyResponse_Byte4:0, base-type=APPLICATION8, compu {phys=raw for raw 0..255}, transfer-property=PENDING, to ECM
          signal NXSI_KeyResponse_Byte5: start 47, 8 bit, big-endian, data-type-policy=OVERRIDE, init-value=Signal_NXSI_KeyResponse_Byte5:0, base-type=APPLICATION8, compu {phys=raw for raw 0..255}, transfer-property=PENDING, to ECM
          signal NXSI_KeyResponse_Byte6: start 55, 8 bit, big-endian, data-type-policy=OVERRIDE, init-value=Signal_NXSI_KeyResponse_Byte6:0, base-type=APPLICATION8, compu {phys=raw for raw 0..255}, transfer-property=PENDING, to ECM
          signal NXSI_KeyResponse_Byte7: start 63, 8 bit, big-endian, data-type-policy=OVERRIDE, init-value=Signal_NXSI_KeyResponse_Byte7:0, base-type=APPLICATION8, compu {phys=raw for raw 0..255}, transfer-property=PENDING, to ECM
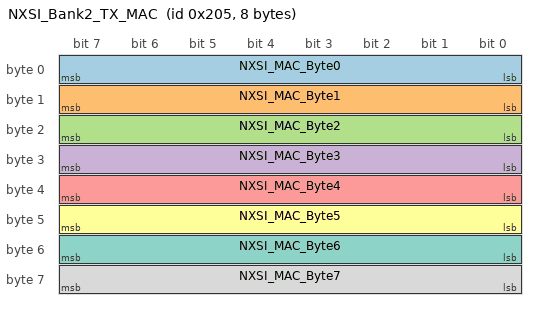
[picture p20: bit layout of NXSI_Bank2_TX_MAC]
      frame NXSI_Bank2_TX_MAC: id 0x205, to ECM, frame-length=8, can-addressing-mode=STANDARD, can-fd-frame-support=false, can-frame-rx-behavior=CAN-20, can-frame-tx-behavior=CAN-20
        carries pdu NXSI_Bank2_TX_MAC: packing-byte-order=big-endian, start-position=7
        pdu NXSI_Bank2_TX_MAC: length=8, unused-bit-pattern=0
          signal NXSI_MAC_Byte0: start 7, 8 bit, big-endian, data-type-policy=OVERRIDE, init-value=Signal_NXSI_MAC_Byte0:0, base-type=APPLICATION8, compu {phys=raw for raw 0..255}, transfer-property=PENDING, to ECM
          signal NXSI_MAC_Byte1: start 15, 8 bit, big-endian, data-type-policy=OVERRIDE, init-value=Signal_NXSI_MAC_Byte1:0, base-type=APPLICATION8, compu {phys=raw for raw 0..255}, transfer-property=PENDING, to ECM
          signal NXSI_MAC_Byte2: start 23, 8 bit, big-endian, data-type-policy=OVERRIDE, init-value=Signal_NXSI_MAC_Byte2:0, base-type=APPLICATION8, compu {phys=raw for raw 0..255}, transfer-property=PENDING, to ECM
          signal NXSI_MAC_Byte3: start 31, 8 bit, big-endian, data-type-policy=OVERRIDE, init-value=Signal_NXSI_MAC_Byte3:0, base-type=APPLICATION8, compu {phys=raw for raw 0..255}, transfer-property=PENDING, to ECM
          signal NXSI_MAC_Byte4: start 39, 8 bit, big-endian, data-type-policy=OVERRIDE, init-value=Signal_NXSI_MAC_Byte4:0, base-type=APPLICATION8, compu {phys=raw for raw 0..255}, transfer-property=PENDING, to ECM
          signal NXSI_MAC_Byte5: start 47, 8 bit, big-endian, data-type-policy=OVERRIDE, init-value=Signal_NXSI_MAC_Byte5:0, base-type=APPLICATION8, compu {phys=raw for raw 0..255}, transfer-property=PENDING, to ECM
          signal NXSI_MAC_Byte6: start 55, 8 bit, big-endian, data-type-policy=OVERRIDE, init-value=Signal_NXSI_MAC_Byte6:0, base-type=APPLICATION8, compu {phys=raw for raw 0..255}, transfer-property=PENDING, to ECM
          signal NXSI_MAC_Byte7: start 63, 8 bit, big-endian, data-type-policy=OVERRIDE, init-value=Signal_NXSI_MAC_Byte7:0, base-type=APPLICATION8, compu {phys=raw for raw 0..255}, transfer-property=PENDING, to ECM
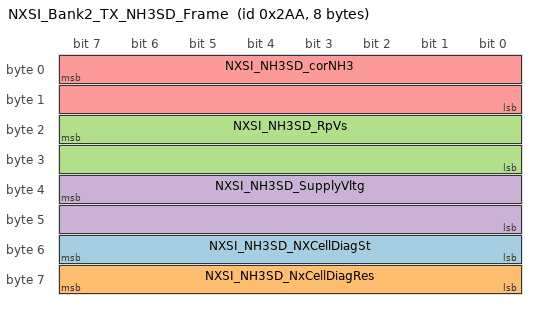
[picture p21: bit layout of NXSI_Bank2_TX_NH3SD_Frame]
      frame NXSI_Bank2_TX_NH3SD_Frame: id 0x2AA, to ECM, frame-length=8, can-addressing-mode=STANDARD, can-fd-frame-support=false, can-frame-rx-behavior=CAN-20, can-frame-tx-behavior=CAN-20
        carries pdu NXSI_Bank2_TX_NH3SD_Frame: packing-byte-order=big-endian, start-position=7
        pdu NXSI_Bank2_TX_NH3SD_Frame: length=8, transmission-mode-true-timing=cyclic-timing=time-period=0.01, unused-bit-pattern=0
          signal NXSI_NH3SD_NXCellDiagSt: start 55, 8 bit, big-endian, data-type-policy=OVERRIDE, init-value=Signal_NXSI_NH3SD_NXCellDiagSt:0, base-type=APPLICATION8, compu-method=DataTypeSemantics/NXSI_NH3SD_NXCellDiagSt_COMPU, transfer-property=PENDING, to ECM
          signal NXSI_NH3SD_NxCellDiagRes: start 63, 8 bit, big-endian, data-type-policy=OVERRIDE, init-value=Signal_NXSI_NH3SD_NxCellDiagRes:0, base-type=APPLICATION8, compu {phys=raw for raw 0..255; unit Unit_%}, transfer-property=PENDING, to ECM
          signal NXSI_NH3SD_RpVs: start 23, 16 bit, big-endian, data-type-policy=OVERRIDE, init-value=Signal_NXSI_NH3SD_RpVs:0, base-type=APPLICATION16, compu {phys=raw*0.01 for raw 0..65535; unit Unit_Ohm}, transfer-property=PENDING, to ECM
          signal NXSI_NH3SD_SupplyVltg: start 39, 16 bit, big-endian, data-type-policy=OVERRIDE, init-value=Signal_NXSI_NH3SD_SupplyVltg:0, base-type=APPLICATION16, compu {phys=raw*0.5 for raw 0..65535; unit Unit_mV}, transfer-property=PENDING, to ECM
          signal NXSI_NH3SD_corNH3: start 7, 16 bit, big-endian, data-type-policy=OVERRIDE, init-value=Signal_NXSI_NH3SD_corNH3:0, base-type=APPLICATION16, compu {phys=raw*0.005 for raw 0..65535}, transfer-property=PENDING, to ECM
      frame Test_Dummy: id 0x1, to ECM, frame-length=8, can-addressing-mode=STANDARD, can-frame-tx-behavior=CAN-20
        pdu Test_Dummy_PDU: length=8
          signal Test_Dummy_PDU_Signal: start 0, 8 bit, little-endian, system signal Test_Dummy_PDU_Signal_404bcb012bbc9ce2, data-type-policy=OVERRIDE, base-type=APPLICATION1, to ECM
package /VectorAutosarExplorerGeneratedObjects/PDU_GROUP
  i signal i pdu group PduGroup_2aab989138b64636877a7f761b5a08a8_Rx: communication-direction=IN
